VERSION ""

NS_ :

BS_:

BU_: Vector__XXX

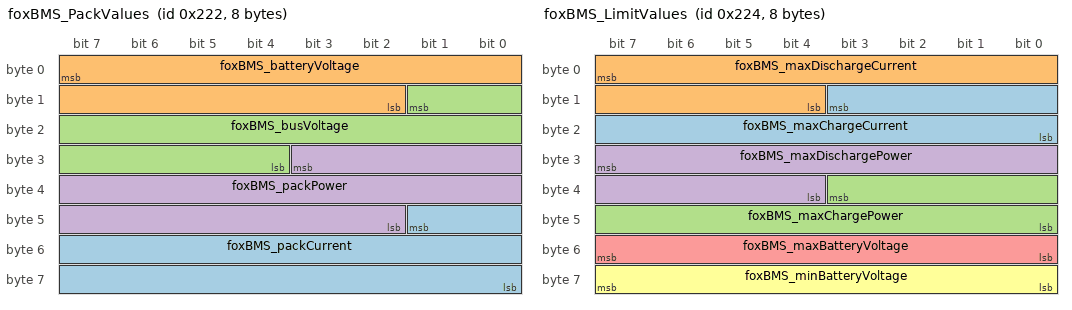
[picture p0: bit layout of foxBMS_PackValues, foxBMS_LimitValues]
BO_ 546 foxBMS_PackValues: 8 Vector__XXX
SG_ foxBMS_packCurrent : 41|18@0- (0.01,0) [-1310.72|1310.71] "A" Vector__XXX
SG_ foxBMS_batteryVoltage : 7|14@0+ (0.1,0) [0|1638.3] "V" Vector__XXX
SG_ foxBMS_busVoltage : 9|14@0+ (0.1,0) [0|1638.3] "V" Vector__XXX
SG_ foxBMS_packPower : 27|18@0- (0.01,0) [-1310.72|1310.71] "kW" Vector__XXX

BO_ 548 foxBMS_LimitValues: 8 Vector__XXX
SG_ foxBMS_maxChargeCurrent : 11|12@0+ (0.25,0) [0|1023.75] "A" Vector__XXX
SG_ foxBMS_maxDischargeCurrent : 7|12@0+ (0.25,0) [0|1023.75] "A" Vector__XXX
SG_ foxBMS_maxChargePower : 35|12@0+ (0.2,0) [0|819] "kW" Vector__XXX
SG_ foxBMS_maxDischargePower : 31|12@0+ (0.1,0) [0|409.5] "kW" Vector__XXX
SG_ foxBMS_maxBatteryVoltage : 55|8@0+ (4,0) [0|1020] "V" Vector__XXX
SG_ foxBMS_minBatteryVoltage : 63|8@0+ (4,0) [0|1020] "V" Vector__XXX

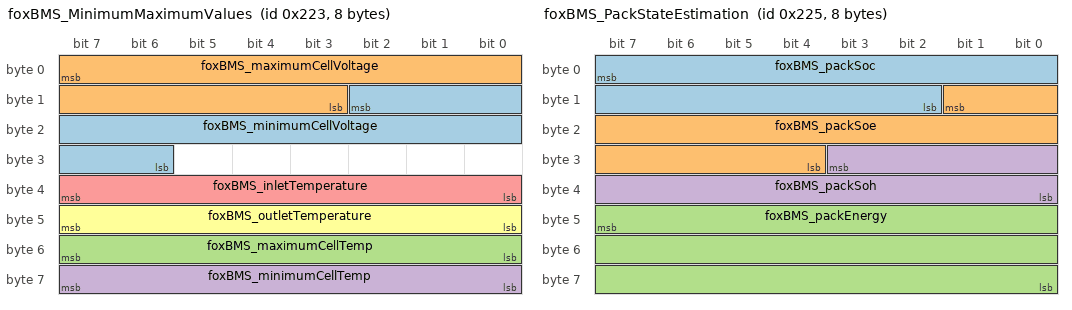
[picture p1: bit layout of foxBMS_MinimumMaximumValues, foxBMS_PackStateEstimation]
BO_ 547 foxBMS_MinimumMaximumValues: 8 Vector__XXX
SG_ foxBMS_minimumCellVoltage : 10|13@0+ (1,0) [0|8191] "mV" Vector__XXX
SG_ foxBMS_maximumCellVoltage : 7|13@0+ (1,0) [0|8191] "mV" Vector__XXX
SG_ foxBMS_maximumCellTemp : 55|8@0- (1,0) [-128|127] "degC" Vector__XXX
SG_ foxBMS_minimumCellTemp : 63|8@0- (1,0) [-128|127] "degC" Vector__XXX
SG_ foxBMS_inletTemperature : 39|8@0- (1,0) [-128|127] "degC" Vector__XXX
SG_ foxBMS_outletTemperature : 47|8@0- (1,0) [-128|127] "degC" Vector__XXX

BO_ 640 foxBMS_StringValues: 8 Vector__XXX
SG_ foxBMS_StringValues_Mux M : 7|3@0+ (1,0) [0|0] "" Vector__XXX
SG_ foxBMS_String0_current m0 : 19|18@0- (0.01,0) [-1310.72|1310.71] "A" Vector__XXX
SG_ foxBMS_String0_voltage m0 : 4|17@0+ (0.01,0) [0|1310.71] "V" Vector__XXX
SG_ foxBMS_String0_power m0 : 33|18@0- (0.01,0) [-1310.72|1310.71] "kW" Vector__XXX
SG_ foxBMS_String1_current m1 : 19|18@0- (0.01,0) [-1310.72|1310.71] "A" Vector__XXX
SG_ foxBMS_String1_voltage m1 : 4|17@0+ (0.01,0) [0|1310.71] "V" Vector__XXX
SG_ foxBMS_String1_power m1 : 33|18@0- (0.01,0) [-1310.72|1310.71] "kW" Vector__XXX
SG_ foxBMS_String2_current m2 : 19|18@0- (0.01,0) [-1310.72|1310.71] "A" Vector__XXX
SG_ foxBMS_String2_voltage m2 : 4|17@0+ (0.01,0) [0|1310.71] "V" Vector__XXX
SG_ foxBMS_String2_power m2 : 33|18@0- (0.01,0) [-1310.72|1310.71] "kW" Vector__XXX

BO_ 643 foxBMS_StringValues2: 8 Vector__XXX
SG_ foxBMS_StringValues2_Mux M : 7|4@0+ (1,0) [0|0] "" Vector__XXX
SG_ String0_energyCount m0 : 15|32@0- (1,0) [-2147483648|2147483647] "Wh" Vector__XXX
SG_ String1_energyCount1 m1 : 15|32@0- (1,0) [-2147483648|2147483647] "Wh" Vector__XXX
SG_ String1_energyCount2 m2 : 15|32@0- (1,0) [-2147483648|2147483647] "Wh" Vector__XXX

BO_ 549 foxBMS_PackStateEstimation: 8 Vector__XXX
SG_ foxBMS_packSoc : 7|14@0+ (0.01,0) [0|163.83] "%" Vector__XXX
SG_ foxBMS_packSoe : 9|14@0+ (0.01,0) [0|163.83] "%" Vector__XXX
SG_ foxBMS_packEnergy : 47|24@0+ (0.01,0) [0|167772.15] "kWh" Vector__XXX
SG_ foxBMS_packSoh : 27|12@0+ (0.025,0) [0|102.375] "%" Vector__XXX

BO_ 576 foxBMS_CellVoltage: 8 Vector__XXX
SG_ foxBMS_CellVoltage_Mux M : 7|8@0+ (1,0) [0|0] "" Vector__XXX
SG_ cellVoltage_0_invalidFlag m0 : 12|1@0+ (1,0) [0|1] "" Vector__XXX
SG_ cellVoltage_1_invalidFlag m0 : 13|1@0+ (1,0) [0|1] "" Vector__XXX
SG_ cellVoltage_2_invalidFlag m0 : 14|1@0+ (1,0) [0|1] "" Vector__XXX
SG_ cellVoltage_3_invalidFlag m0 : 15|1@0+ (1,0) [0|1] "" Vector__XXX
SG_ cellVoltage_0 m0 : 11|13@0+ (1,0) [0|8191] "mV" Vector__XXX
SG_ cell_voltage_1 m0 : 30|13@0+ (1,0) [0|8191] "mV" Vector__XXX
SG_ cell_voltage_2 m0 : 33|13@0+ (1,0) [0|8191] "mV" Vector__XXX
SG_ cell_voltage_3 m0 : 52|13@0+ (1,0) [0|8191] "mV" Vector__XXX
SG_ cellVoltage_4_invalidFlag m1 : 12|1@0+ (1,0) [0|1] "" Vector__XXX
SG_ cellVoltage_5_invalidFlag m1 : 13|1@0+ (1,0) [0|1] "" Vector__XXX
SG_ cellVoltage_6_invalidFlag m1 : 14|1@0+ (1,0) [0|1] "" Vector__XXX
SG_ cellVoltage_7_invalidFlag m1 : 15|1@0+ (1,0) [0|1] "" Vector__XXX
SG_ cellVoltage_4 m1 : 11|13@0+ (1,0) [0|8191] "mV" Vector__XXX
SG_ cell_voltage_5 m1 : 30|13@0+ (1,0) [0|8191] "mV" Vector__XXX
SG_ cell_voltage_6 m1 : 33|13@0+ (1,0) [0|8191] "mV" Vector__XXX
SG_ cell_voltage_7 m1 : 52|13@0+ (1,0) [0|8191] "mV" Vector__XXX
SG_ cellVoltage_8_invalidFlag m2 : 12|1@0+ (1,0) [0|1] "" Vector__XXX
SG_ cellVoltage_9_invalidFlag m2 : 13|1@0+ (1,0) [0|1] "" Vector__XXX
SG_ cellVoltage_10_invalidFlag m2 : 14|1@0+ (1,0) [0|1] "" Vector__XXX
SG_ cellVoltage_11_invalidFlag m2 : 15|1@0+ (1,0) [0|1] "" Vector__XXX
SG_ cellVoltage_8 m2 : 11|13@0+ (1,0) [0|8191] "mV" Vector__XXX
SG_ cell_voltage_9 m2 : 30|13@0+ (1,0) [0|8191] "mV" Vector__XXX
SG_ cell_voltage_10 m2 : 33|13@0+ (1,0) [0|8191] "mV" Vector__XXX
SG_ cell_voltage_11 m2 : 52|13@0+ (1,0) [0|8191] "mV" Vector__XXX
SG_ cellVoltage_12_invalidFlag m3 : 12|1@0+ (1,0) [0|1] "" Vector__XXX
SG_ cellVoltage_13_invalidFlag m3 : 13|1@0+ (1,0) [0|1] "" Vector__XXX
SG_ cellVoltage_14_invalidFlag m3 : 14|1@0+ (1,0) [0|1] "" Vector__XXX
SG_ cellVoltage_15_invalidFlag m3 : 15|1@0+ (1,0) [0|1] "" Vector__XXX
SG_ cellVoltage_12 m3 : 11|13@0+ (1,0) [0|8191] "mV" Vector__XXX
SG_ cell_voltage_13 m3 : 30|13@0+ (1,0) [0|8191] "mV" Vector__XXX
SG_ cell_voltage_14 m3 : 33|13@0+ (1,0) [0|8191] "mV" Vector__XXX
SG_ cell_voltage_15 m3 : 52|13@0+ (1,0) [0|8191] "mV" Vector__XXX
SG_ cellVoltage_16_invalidFlag m4 : 12|1@0+ (1,0) [0|1] "" Vector__XXX
SG_ cellVoltage_17_invalidFlag m4 : 13|1@0+ (1,0) [0|1] "" Vector__XXX
SG_ cellVoltage_18_invalidFlag m4 : 14|1@0+ (1,0) [0|1] "" Vector__XXX
SG_ cellVoltage_19_invalidFlag m4 : 15|1@0+ (1,0) [0|1] "" Vector__XXX
SG_ cellVoltage_16 m4 : 11|13@0+ (1,0) [0|8191] "mV" Vector__XXX
SG_ cell_voltage_17 m4 : 30|13@0+ (1,0) [0|8191] "mV" Vector__XXX
SG_ cell_voltage_18 m4 : 33|13@0+ (1,0) [0|8191] "mV" Vector__XXX
SG_ cell_voltage_19 m4 : 52|13@0+ (1,0) [0|8191] "mV" Vector__XXX
SG_ cellVoltage_20_invalidFlag m5 : 12|1@0+ (1,0) [0|1] "" Vector__XXX
SG_ cellVoltage_21_invalidFlag m5 : 13|1@0+ (1,0) [0|1] "" Vector__XXX
SG_ cellVoltage_22_invalidFlag m5 : 14|1@0+ (1,0) [0|1] "" Vector__XXX
SG_ cellVoltage_23_invalidFlag m5 : 15|1@0+ (1,0) [0|1] "" Vector__XXX
SG_ cellVoltage_20 m5 : 11|13@0+ (1,0) [0|8191] "mV" Vector__XXX
SG_ cell_voltage_21 m5 : 30|13@0+ (1,0) [0|8191] "mV" Vector__XXX
SG_ cell_voltage_22 m5 : 33|13@0+ (1,0) [0|8191] "mV" Vector__XXX
SG_ cell_voltage_23 m5 : 52|13@0+ (1,0) [0|8191] "mV" Vector__XXX
SG_ cellVoltage_24_invalidFlag m6 : 12|1@0+ (1,0) [0|1] "" Vector__XXX
SG_ cellVoltage_25_invalidFlag m6 : 13|1@0+ (1,0) [0|1] "" Vector__XXX
SG_ cellVoltage_26_invalidFlag m6 : 14|1@0+ (1,0) [0|1] "" Vector__XXX
SG_ cellVoltage_27_invalidFlag m6 : 15|1@0+ (1,0) [0|1] "" Vector__XXX
SG_ cellVoltage_24 m6 : 11|13@0+ (1,0) [0|8191] "mV" Vector__XXX
SG_ cell_voltage_25 m6 : 30|13@0+ (1,0) [0|8191] "mV" Vector__XXX
SG_ cell_voltage_26 m6 : 33|13@0+ (1,0) [0|8191] "mV" Vector__XXX
SG_ cell_voltage_27 m6 : 52|13@0+ (1,0) [0|8191] "mV" Vector__XXX
SG_ cellVoltage_28_invalidFlag m7 : 12|1@0+ (1,0) [0|1] "" Vector__XXX
SG_ cellVoltage_29_invalidFlag m7 : 13|1@0+ (1,0) [0|1] "" Vector__XXX
SG_ cellVoltage_30_invalidFlag m7 : 14|1@0+ (1,0) [0|1] "" Vector__XXX
SG_ cellVoltage_31_invalidFlag m7 : 15|1@0+ (1,0) [0|1] "" Vector__XXX
SG_ cellVoltage_28 m7 : 11|13@0+ (1,0) [0|8191] "mV" Vector__XXX
SG_ cell_voltage_29 m7 : 30|13@0+ (1,0) [0|8191] "mV" Vector__XXX
SG_ cell_voltage_30 m7 : 33|13@0+ (1,0) [0|8191] "mV" Vector__XXX
SG_ cell_voltage_31 m7 : 52|13@0+ (1,0) [0|8191] "mV" Vector__XXX
SG_ cellVoltage_32_invalidFlag m8 : 12|1@0+ (1,0) [0|1] "" Vector__XXX
SG_ cellVoltage_33_invalidFlag m8 : 13|1@0+ (1,0) [0|1] "" Vector__XXX
SG_ cellVoltage_34_invalidFlag m8 : 14|1@0+ (1,0) [0|1] "" Vector__XXX
SG_ cellVoltage_35_invalidFlag m8 : 15|1@0+ (1,0) [0|1] "" Vector__XXX
SG_ cellVoltage_32 m8 : 11|13@0+ (1,0) [0|8191] "mV" Vector__XXX
SG_ cell_voltage_33 m8 : 30|13@0+ (1,0) [0|8191] "mV" Vector__XXX
SG_ cell_voltage_34 m8 : 33|13@0+ (1,0) [0|8191] "mV" Vector__XXX
SG_ cell_voltage_35 m8 : 52|13@0+ (1,0) [0|8191] "mV" Vector__XXX
SG_ cellVoltage_36_invalidFlag m9 : 12|1@0+ (1,0) [0|1] "" Vector__XXX
SG_ cellVoltage_37_invalidFlag m9 : 13|1@0+ (1,0) [0|1] "" Vector__XXX
SG_ cellVoltage_38_invalidFlag m9 : 14|1@0+ (1,0) [0|1] "" Vector__XXX
SG_ cellVoltage_39_invalidFlag m9 : 15|1@0+ (1,0) [0|1] "" Vector__XXX
SG_ cellVoltage_36 m9 : 11|13@0+ (1,0) [0|8191] "mV" Vector__XXX
SG_ cell_voltage_37 m9 : 30|13@0+ (1,0) [0|8191] "mV" Vector__XXX
SG_ cell_voltage_38 m9 : 33|13@0+ (1,0) [0|8191] "mV" Vector__XXX
SG_ cell_voltage_39 m9 : 52|13@0+ (1,0) [0|8191] "mV" Vector__XXX
SG_ cellVoltage_40_invalidFlag m10 : 12|1@0+ (1,0) [0|1] "" Vector__XXX
SG_ cellVoltage_41_invalidFlag m10 : 13|1@0+ (1,0) [0|1] "" Vector__XXX
SG_ cellVoltage_42_invalidFlag m10 : 14|1@0+ (1,0) [0|1] "" Vector__XXX
SG_ cellVoltage_43_invalidFlag m10 : 15|1@0+ (1,0) [0|1] "" Vector__XXX
SG_ cellVoltage_40 m10 : 11|13@0+ (1,0) [0|8191] "mV" Vector__XXX
SG_ cell_voltage_41 m10 : 30|13@0+ (1,0) [0|8191] "mV" Vector__XXX
SG_ cell_voltage_42 m10 : 33|13@0+ (1,0) [0|8191] "mV" Vector__XXX
SG_ cell_voltage_43 m10 : 52|13@0+ (1,0) [0|8191] "mV" Vector__XXX
SG_ cellVoltage_44_invalidFlag m11 : 12|1@0+ (1,0) [0|1] "" Vector__XXX
SG_ cellVoltage_45_invalidFlag m11 : 13|1@0+ (1,0) [0|1] "" Vector__XXX
SG_ cellVoltage_46_invalidFlag m11 : 14|1@0+ (1,0) [0|1] "" Vector__XXX
SG_ cellVoltage_47_invalidFlag m11 : 15|1@0+ (1,0) [0|1] "" Vector__XXX
SG_ cellVoltage_44 m11 : 11|13@0+ (1,0) [0|8191] "mV" Vector__XXX
SG_ cell_voltage_45 m11 : 30|13@0+ (1,0) [0|8191] "mV" Vector__XXX
SG_ cell_voltage_46 m11 : 33|13@0+ (1,0) [0|8191] "mV" Vector__XXX
SG_ cell_voltage_47 m11 : 52|13@0+ (1,0) [0|8191] "mV" Vector__XXX
SG_ cellVoltage_48_invalidFlag m12 : 12|1@0+ (1,0) [0|1] "" Vector__XXX
SG_ cellVoltage_49_invalidFlag m12 : 13|1@0+ (1,0) [0|1] "" Vector__XXX
SG_ cellVoltage_50_invalidFlag m12 : 14|1@0+ (1,0) [0|1] "" Vector__XXX
SG_ cellVoltage_51_invalidFlag m12 : 15|1@0+ (1,0) [0|1] "" Vector__XXX
SG_ cellVoltage_48 m12 : 11|13@0+ (1,0) [0|8191] "mV" Vector__XXX
SG_ cell_voltage_49 m12 : 30|13@0+ (1,0) [0|8191] "mV" Vector__XXX
SG_ cell_voltage_50 m12 : 33|13@0+ (1,0) [0|8191] "mV" Vector__XXX
SG_ cell_voltage_51 m12 : 52|13@0+ (1,0) [0|8191] "mV" Vector__XXX
SG_ cellVoltage_52_invalidFlag m13 : 12|1@0+ (1,0) [0|1] "" Vector__XXX
SG_ cellVoltage_53_invalidFlag m13 : 13|1@0+ (1,0) [0|1] "" Vector__XXX
SG_ cellVoltage_54_invalidFlag m13 : 14|1@0+ (1,0) [0|1] "" Vector__XXX
SG_ cellVoltage_55_invalidFlag m13 : 15|1@0+ (1,0) [0|1] "" Vector__XXX
SG_ cellVoltage_52 m13 : 11|13@0+ (1,0) [0|8191] "mV" Vector__XXX
SG_ cell_voltage_53 m13 : 30|13@0+ (1,0) [0|8191] "mV" Vector__XXX
SG_ cell_voltage_54 m13 : 33|13@0+ (1,0) [0|8191] "mV" Vector__XXX
SG_ cell_voltage_55 m13 : 52|13@0+ (1,0) [0|8191] "mV" Vector__XXX
SG_ cellVoltage_56_invalidFlag m14 : 12|1@0+ (1,0) [0|1] "" Vector__XXX
SG_ cellVoltage_57_invalidFlag m14 : 13|1@0+ (1,0) [0|1] "" Vector__XXX
SG_ cellVoltage_58_invalidFlag m14 : 14|1@0+ (1,0) [0|1] "" Vector__XXX
SG_ cellVoltage_59_invalidFlag m14 : 15|1@0+ (1,0) [0|1] "" Vector__XXX
SG_ cellVoltage_56 m14 : 11|13@0+ (1,0) [0|8191] "mV" Vector__XXX
SG_ cell_voltage_57 m14 : 30|13@0+ (1,0) [0|8191] "mV" Vector__XXX
SG_ cell_voltage_58 m14 : 33|13@0+ (1,0) [0|8191] "mV" Vector__XXX
SG_ cell_voltage_59 m14 : 52|13@0+ (1,0) [0|8191] "mV" Vector__XXX
SG_ cellVoltage_60_invalidFlag m15 : 12|1@0+ (1,0) [0|1] "" Vector__XXX
SG_ cellVoltage_61_invalidFlag m15 : 13|1@0+ (1,0) [0|1] "" Vector__XXX
SG_ cellVoltage_62_invalidFlag m15 : 14|1@0+ (1,0) [0|1] "" Vector__XXX
SG_ cellVoltage_63_invalidFlag m15 : 15|1@0+ (1,0) [0|1] "" Vector__XXX
SG_ cellVoltage_60 m15 : 11|13@0+ (1,0) [0|8191] "mV" Vector__XXX
SG_ cell_voltage_61 m15 : 30|13@0+ (1,0) [0|8191] "mV" Vector__XXX
SG_ cell_voltage_62 m15 : 33|13@0+ (1,0) [0|8191] "mV" Vector__XXX
SG_ cell_voltage_63 m15 : 52|13@0+ (1,0) [0|8191] "mV" Vector__XXX
SG_ cellVoltage_64_invalidFlag m16 : 12|1@0+ (1,0) [0|1] "" Vector__XXX
SG_ cellVoltage_65_invalidFlag m16 : 13|1@0+ (1,0) [0|1] "" Vector__XXX
SG_ cellVoltage_66_invalidFlag m16 : 14|1@0+ (1,0) [0|1] "" Vector__XXX
SG_ cellVoltage_67_invalidFlag m16 : 15|1@0+ (1,0) [0|1] "" Vector__XXX
SG_ cellVoltage_64 m16 : 11|13@0+ (1,0) [0|8191] "mV" Vector__XXX
SG_ cell_voltage_65 m16 : 30|13@0+ (1,0) [0|8191] "mV" Vector__XXX
SG_ cell_voltage_66 m16 : 33|13@0+ (1,0) [0|8191] "mV" Vector__XXX
SG_ cell_voltage_67 m16 : 52|13@0+ (1,0) [0|8191] "mV" Vector__XXX
SG_ cellVoltage_68_invalidFlag m17 : 12|1@0+ (1,0) [0|1] "" Vector__XXX
SG_ cellVoltage_69_invalidFlag m17 : 13|1@0+ (1,0) [0|1] "" Vector__XXX
SG_ cellVoltage_70_invalidFlag m17 : 14|1@0+ (1,0) [0|1] "" Vector__XXX
SG_ cellVoltage_71_invalidFlag m17 : 15|1@0+ (1,0) [0|1] "" Vector__XXX
SG_ cellVoltage_68 m17 : 11|13@0+ (1,0) [0|8191] "mV" Vector__XXX
SG_ cell_voltage_69 m17 : 30|13@0+ (1,0) [0|8191] "mV" Vector__XXX
SG_ cell_voltage_70 m17 : 33|13@0+ (1,0) [0|8191] "mV" Vector__XXX
SG_ cell_voltage_71 m17 : 52|13@0+ (1,0) [0|8191] "mV" Vector__XXX
SG_ cellVoltage_72_invalidFlag m18 : 12|1@0+ (1,0) [0|1] "" Vector__XXX
SG_ cellVoltage_73_invalidFlag m18 : 13|1@0+ (1,0) [0|1] "" Vector__XXX
SG_ cellVoltage_74_invalidFlag m18 : 14|1@0+ (1,0) [0|1] "" Vector__XXX
SG_ cellVoltage_75_invalidFlag m18 : 15|1@0+ (1,0) [0|1] "" Vector__XXX
SG_ cellVoltage_72 m18 : 11|13@0+ (1,0) [0|8191] "mV" Vector__XXX
SG_ cell_voltage_73 m18 : 30|13@0+ (1,0) [0|8191] "mV" Vector__XXX
SG_ cell_voltage_74 m18 : 33|13@0+ (1,0) [0|8191] "mV" Vector__XXX
SG_ cell_voltage_75 m18 : 52|13@0+ (1,0) [0|8191] "mV" Vector__XXX
SG_ cellVoltage_76_invalidFlag m19 : 12|1@0+ (1,0) [0|1] "" Vector__XXX
SG_ cellVoltage_77_invalidFlag m19 : 13|1@0+ (1,0) [0|1] "" Vector__XXX
SG_ cellVoltage_78_invalidFlag m19 : 14|1@0+ (1,0) [0|1] "" Vector__XXX
SG_ cellVoltage_79_invalidFlag m19 : 15|1@0+ (1,0) [0|1] "" Vector__XXX
SG_ cellVoltage_76 m19 : 11|13@0+ (1,0) [0|8191] "mV" Vector__XXX
SG_ cell_voltage_77 m19 : 30|13@0+ (1,0) [0|8191] "mV" Vector__XXX
SG_ cell_voltage_78 m19 : 33|13@0+ (1,0) [0|8191] "mV" Vector__XXX
SG_ cell_voltage_79 m19 : 52|13@0+ (1,0) [0|8191] "mV" Vector__XXX
SG_ cellVoltage_80_invalidFlag m20 : 12|1@0+ (1,0) [0|1] "" Vector__XXX
SG_ cellVoltage_81_invalidFlag m20 : 13|1@0+ (1,0) [0|1] "" Vector__XXX
SG_ cellVoltage_82_invalidFlag m20 : 14|1@0+ (1,0) [0|1] "" Vector__XXX
SG_ cellVoltage_83_invalidFlag m20 : 15|1@0+ (1,0) [0|1] "" Vector__XXX
SG_ cellVoltage_80 m20 : 11|13@0+ (1,0) [0|8191] "mV" Vector__XXX
SG_ cell_voltage_81 m20 : 30|13@0+ (1,0) [0|8191] "mV" Vector__XXX
SG_ cell_voltage_82 m20 : 33|13@0+ (1,0) [0|8191] "mV" Vector__XXX
SG_ cell_voltage_83 m20 : 52|13@0+ (1,0) [0|8191] "mV" Vector__XXX
SG_ cellVoltage_84_invalidFlag m21 : 12|1@0+ (1,0) [0|1] "" Vector__XXX
SG_ cellVoltage_85_invalidFlag m21 : 13|1@0+ (1,0) [0|1] "" Vector__XXX
SG_ cellVoltage_86_invalidFlag m21 : 14|1@0+ (1,0) [0|1] "" Vector__XXX
SG_ cellVoltage_87_invalidFlag m21 : 15|1@0+ (1,0) [0|1] "" Vector__XXX
SG_ cellVoltage_84 m21 : 11|13@0+ (1,0) [0|8191] "mV" Vector__XXX
SG_ cell_voltage_85 m21 : 30|13@0+ (1,0) [0|8191] "mV" Vector__XXX
SG_ cell_voltage_86 m21 : 33|13@0+ (1,0) [0|8191] "mV" Vector__XXX
SG_ cell_voltage_87 m21 : 52|13@0+ (1,0) [0|8191] "mV" Vector__XXX
SG_ cellVoltage_88_invalidFlag m22 : 12|1@0+ (1,0) [0|1] "" Vector__XXX
SG_ cellVoltage_89_invalidFlag m22 : 13|1@0+ (1,0) [0|1] "" Vector__XXX
SG_ cellVoltage_90_invalidFlag m22 : 14|1@0+ (1,0) [0|1] "" Vector__XXX
SG_ cellVoltage_91_invalidFlag m22 : 15|1@0+ (1,0) [0|1] "" Vector__XXX
SG_ cellVoltage_88 m22 : 11|13@0+ (1,0) [0|8191] "mV" Vector__XXX
SG_ cell_voltage_89 m22 : 30|13@0+ (1,0) [0|8191] "mV" Vector__XXX
SG_ cell_voltage_90 m22 : 33|13@0+ (1,0) [0|8191] "mV" Vector__XXX
SG_ cell_voltage_91 m22 : 52|13@0+ (1,0) [0|8191] "mV" Vector__XXX
SG_ cellVoltage_92_invalidFlag m23 : 12|1@0+ (1,0) [0|1] "" Vector__XXX
SG_ cellVoltage_93_invalidFlag m23 : 13|1@0+ (1,0) [0|1] "" Vector__XXX
SG_ cellVoltage_94_invalidFlag m23 : 14|1@0+ (1,0) [0|1] "" Vector__XXX
SG_ cellVoltage_95_invalidFlag m23 : 15|1@0+ (1,0) [0|1] "" Vector__XXX
SG_ cellVoltage_92 m23 : 11|13@0+ (1,0) [0|8191] "mV" Vector__XXX
SG_ cell_voltage_93 m23 : 30|13@0+ (1,0) [0|8191] "mV" Vector__XXX
SG_ cell_voltage_94 m23 : 33|13@0+ (1,0) [0|8191] "mV" Vector__XXX
SG_ cell_voltage_95 m23 : 52|13@0+ (1,0) [0|8191] "mV" Vector__XXX
SG_ cellVoltage_96_invalidFlag m24 : 12|1@0+ (1,0) [0|1] "" Vector__XXX
SG_ cellVoltage_97_invalidFlag m24 : 13|1@0+ (1,0) [0|1] "" Vector__XXX
SG_ cellVoltage_98_invalidFlag m24 : 14|1@0+ (1,0) [0|1] "" Vector__XXX
SG_ cellVoltage_99_invalidFlag m24 : 15|1@0+ (1,0) [0|1] "" Vector__XXX
SG_ cellVoltage_96 m24 : 11|13@0+ (1,0) [0|8191] "mV" Vector__XXX
SG_ cell_voltage_97 m24 : 30|13@0+ (1,0) [0|8191] "mV" Vector__XXX
SG_ cell_voltage_98 m24 : 33|13@0+ (1,0) [0|8191] "mV" Vector__XXX
SG_ cell_voltage_99 m24 : 52|13@0+ (1,0) [0|8191] "mV" Vector__XXX
SG_ cellVoltage_100_invalidFlag m25 : 12|1@0+ (1,0) [0|1] "" Vector__XXX
SG_ cellVoltage_101_invalidFlag m25 : 13|1@0+ (1,0) [0|1] "" Vector__XXX
SG_ cellVoltage_102_invalidFlag m25 : 14|1@0+ (1,0) [0|1] "" Vector__XXX
SG_ cellVoltage_103_invalidFlag m25 : 15|1@0+ (1,0) [0|1] "" Vector__XXX
SG_ cellVoltage_100 m25 : 11|13@0+ (1,0) [0|8191] "mV" Vector__XXX
SG_ cell_voltage_101 m25 : 30|13@0+ (1,0) [0|8191] "mV" Vector__XXX
SG_ cell_voltage_102 m25 : 33|13@0+ (1,0) [0|8191] "mV" Vector__XXX
SG_ cell_voltage_103 m25 : 52|13@0+ (1,0) [0|8191] "mV" Vector__XXX
SG_ cellVoltage_104_invalidFlag m26 : 12|1@0+ (1,0) [0|1] "" Vector__XXX
SG_ cellVoltage_105_invalidFlag m26 : 13|1@0+ (1,0) [0|1] "" Vector__XXX
SG_ cellVoltage_106_invalidFlag m26 : 14|1@0+ (1,0) [0|1] "" Vector__XXX
SG_ cellVoltage_107_invalidFlag m26 : 15|1@0+ (1,0) [0|1] "" Vector__XXX
SG_ cellVoltage_104 m26 : 11|13@0+ (1,0) [0|8191] "mV" Vector__XXX
SG_ cell_voltage_105 m26 : 30|13@0+ (1,0) [0|8191] "mV" Vector__XXX
SG_ cell_voltage_106 m26 : 33|13@0+ (1,0) [0|8191] "mV" Vector__XXX
SG_ cell_voltage_107 m26 : 52|13@0+ (1,0) [0|8191] "mV" Vector__XXX
SG_ cellVoltage_108_invalidFlag m27 : 12|1@0+ (1,0) [0|1] "" Vector__XXX
SG_ cellVoltage_109_invalidFlag m27 : 13|1@0+ (1,0) [0|1] "" Vector__XXX
SG_ cellVoltage_110_invalidFlag m27 : 14|1@0+ (1,0) [0|1] "" Vector__XXX
SG_ cellVoltage_111_invalidFlag m27 : 15|1@0+ (1,0) [0|1] "" Vector__XXX
SG_ cellVoltage_108 m27 : 11|13@0+ (1,0) [0|8191] "mV" Vector__XXX
SG_ cell_voltage_109 m27 : 30|13@0+ (1,0) [0|8191] "mV" Vector__XXX
SG_ cell_voltage_110 m27 : 33|13@0+ (1,0) [0|8191] "mV" Vector__XXX
SG_ cell_voltage_111 m27 : 52|13@0+ (1,0) [0|8191] "mV" Vector__XXX
SG_ cellVoltage_112_invalidFlag m28 : 12|1@0+ (1,0) [0|1] "" Vector__XXX
SG_ cellVoltage_113_invalidFlag m28 : 13|1@0+ (1,0) [0|1] "" Vector__XXX
SG_ cellVoltage_114_invalidFlag m28 : 14|1@0+ (1,0) [0|1] "" Vector__XXX
SG_ cellVoltage_115_invalidFlag m28 : 15|1@0+ (1,0) [0|1] "" Vector__XXX
SG_ cellVoltage_112 m28 : 11|13@0+ (1,0) [0|8191] "mV" Vector__XXX
SG_ cell_voltage_113 m28 : 30|13@0+ (1,0) [0|8191] "mV" Vector__XXX
SG_ cell_voltage_114 m28 : 33|13@0+ (1,0) [0|8191] "mV" Vector__XXX
SG_ cell_voltage_115 m28 : 52|13@0+ (1,0) [0|8191] "mV" Vector__XXX
SG_ cellVoltage_116_invalidFlag m29 : 12|1@0+ (1,0) [0|1] "" Vector__XXX
SG_ cellVoltage_117_invalidFlag m29 : 13|1@0+ (1,0) [0|1] "" Vector__XXX
SG_ cellVoltage_118_invalidFlag m29 : 14|1@0+ (1,0) [0|1] "" Vector__XXX
SG_ cellVoltage_119_invalidFlag m29 : 15|1@0+ (1,0) [0|1] "" Vector__XXX
SG_ cellVoltage_116 m29 : 11|13@0+ (1,0) [0|8191] "mV" Vector__XXX
SG_ cell_voltage_117 m29 : 30|13@0+ (1,0) [0|8191] "mV" Vector__XXX
SG_ cell_voltage_118 m29 : 33|13@0+ (1,0) [0|8191] "mV" Vector__XXX
SG_ cell_voltage_119 m29 : 52|13@0+ (1,0) [0|8191] "mV" Vector__XXX
SG_ cellVoltage_120_invalidFlag m30 : 12|1@0+ (1,0) [0|1] "" Vector__XXX
SG_ cellVoltage_121_invalidFlag m30 : 13|1@0+ (1,0) [0|1] "" Vector__XXX
SG_ cellVoltage_122_invalidFlag m30 : 14|1@0+ (1,0) [0|1] "" Vector__XXX
SG_ cellVoltage_123_invalidFlag m30 : 15|1@0+ (1,0) [0|1] "" Vector__XXX
SG_ cellVoltage_120 m30 : 11|13@0+ (1,0) [0|8191] "mV" Vector__XXX
SG_ cell_voltage_121 m30 : 30|13@0+ (1,0) [0|8191] "mV" Vector__XXX
SG_ cell_voltage_122 m30 : 33|13@0+ (1,0) [0|8191] "mV" Vector__XXX
SG_ cell_voltage_123 m30 : 52|13@0+ (1,0) [0|8191] "mV" Vector__XXX
SG_ cellVoltage_124_invalidFlag m31 : 12|1@0+ (1,0) [0|1] "" Vector__XXX
SG_ cellVoltage_125_invalidFlag m31 : 13|1@0+ (1,0) [0|1] "" Vector__XXX
SG_ cellVoltage_126_invalidFlag m31 : 14|1@0+ (1,0) [0|1] "" Vector__XXX
SG_ cellVoltage_127_invalidFlag m31 : 15|1@0+ (1,0) [0|1] "" Vector__XXX
SG_ cellVoltage_124 m31 : 11|13@0+ (1,0) [0|8191] "mV" Vector__XXX
SG_ cell_voltage_125 m31 : 30|13@0+ (1,0) [0|8191] "mV" Vector__XXX
SG_ cell_voltage_126 m31 : 33|13@0+ (1,0) [0|8191] "mV" Vector__XXX
SG_ cell_voltage_127 m31 : 52|13@0+ (1,0) [0|8191] "mV" Vector__XXX
SG_ cellVoltage_128_invalidFlag m32 : 12|1@0+ (1,0) [0|1] "" Vector__XXX
SG_ cellVoltage_129_invalidFlag m32 : 13|1@0+ (1,0) [0|1] "" Vector__XXX
SG_ cellVoltage_130_invalidFlag m32 : 14|1@0+ (1,0) [0|1] "" Vector__XXX
SG_ cellVoltage_131_invalidFlag m32 : 15|1@0+ (1,0) [0|1] "" Vector__XXX
SG_ cellVoltage_128 m32 : 11|13@0+ (1,0) [0|8191] "mV" Vector__XXX
SG_ cell_voltage_129 m32 : 30|13@0+ (1,0) [0|8191] "mV" Vector__XXX
SG_ cell_voltage_130 m32 : 33|13@0+ (1,0) [0|8191] "mV" Vector__XXX
SG_ cell_voltage_131 m32 : 52|13@0+ (1,0) [0|8191] "mV" Vector__XXX
SG_ cellVoltage_132_invalidFlag m33 : 12|1@0+ (1,0) [0|1] "" Vector__XXX
SG_ cellVoltage_133_invalidFlag m33 : 13|1@0+ (1,0) [0|1] "" Vector__XXX
SG_ cellVoltage_134_invalidFlag m33 : 14|1@0+ (1,0) [0|1] "" Vector__XXX
SG_ cellVoltage_135_invalidFlag m33 : 15|1@0+ (1,0) [0|1] "" Vector__XXX
SG_ cellVoltage_132 m33 : 11|13@0+ (1,0) [0|8191] "mV" Vector__XXX
SG_ cell_voltage_133 m33 : 30|13@0+ (1,0) [0|8191] "mV" Vector__XXX
SG_ cell_voltage_134 m33 : 33|13@0+ (1,0) [0|8191] "mV" Vector__XXX
SG_ cell_voltage_135 m33 : 52|13@0+ (1,0) [0|8191] "mV" Vector__XXX
SG_ cellVoltage_136_invalidFlag m34 : 12|1@0+ (1,0) [0|1] "" Vector__XXX
SG_ cellVoltage_137_invalidFlag m34 : 13|1@0+ (1,0) [0|1] "" Vector__XXX
SG_ cellVoltage_138_invalidFlag m34 : 14|1@0+ (1,0) [0|1] "" Vector__XXX
SG_ cellVoltage_139_invalidFlag m34 : 15|1@0+ (1,0) [0|1] "" Vector__XXX
SG_ cellVoltage_136 m34 : 11|13@0+ (1,0) [0|8191] "mV" Vector__XXX
SG_ cell_voltage_137 m34 : 30|13@0+ (1,0) [0|8191] "mV" Vector__XXX
SG_ cell_voltage_138 m34 : 33|13@0+ (1,0) [0|8191] "mV" Vector__XXX
SG_ cell_voltage_139 m34 : 52|13@0+ (1,0) [0|8191] "mV" Vector__XXX
SG_ cellVoltage_140_invalidFlag m35 : 12|1@0+ (1,0) [0|1] "" Vector__XXX
SG_ cellVoltage_141_invalidFlag m35 : 13|1@0+ (1,0) [0|1] "" Vector__XXX
SG_ cellVoltage_142_invalidFlag m35 : 14|1@0+ (1,0) [0|1] "" Vector__XXX
SG_ cellVoltage_143_invalidFlag m35 : 15|1@0+ (1,0) [0|1] "" Vector__XXX
SG_ cellVoltage_140 m35 : 11|13@0+ (1,0) [0|8191] "mV" Vector__XXX
SG_ cell_voltage_141 m35 : 30|13@0+ (1,0) [0|8191] "mV" Vector__XXX
SG_ cell_voltage_142 m35 : 33|13@0+ (1,0) [0|8191] "mV" Vector__XXX
SG_ cell_voltage_143 m35 : 52|13@0+ (1,0) [0|8191] "mV" Vector__XXX
SG_ cellVoltage_144_invalidFlag m36 : 12|1@0+ (1,0) [0|1] "" Vector__XXX
SG_ cellVoltage_145_invalidFlag m36 : 13|1@0+ (1,0) [0|1] "" Vector__XXX
SG_ cellVoltage_146_invalidFlag m36 : 14|1@0+ (1,0) [0|1] "" Vector__XXX
SG_ cellVoltage_147_invalidFlag m36 : 15|1@0+ (1,0) [0|1] "" Vector__XXX
SG_ cellVoltage_144 m36 : 11|13@0+ (1,0) [0|8191] "mV" Vector__XXX
SG_ cell_voltage_145 m36 : 30|13@0+ (1,0) [0|8191] "mV" Vector__XXX
SG_ cell_voltage_146 m36 : 33|13@0+ (1,0) [0|8191] "mV" Vector__XXX
SG_ cell_voltage_147 m36 : 52|13@0+ (1,0) [0|8191] "mV" Vector__XXX
SG_ cellVoltage_148_invalidFlag m37 : 12|1@0+ (1,0) [0|1] "" Vector__XXX
SG_ cellVoltage_149_invalidFlag m37 : 13|1@0+ (1,0) [0|1] "" Vector__XXX
SG_ cellVoltage_150_invalidFlag m37 : 14|1@0+ (1,0) [0|1] "" Vector__XXX
SG_ cellVoltage_151_invalidFlag m37 : 15|1@0+ (1,0) [0|1] "" Vector__XXX
SG_ cellVoltage_148 m37 : 11|13@0+ (1,0) [0|8191] "mV" Vector__XXX
SG_ cell_voltage_149 m37 : 30|13@0+ (1,0) [0|8191] "mV" Vector__XXX
SG_ cell_voltage_150 m37 : 33|13@0+ (1,0) [0|8191] "mV" Vector__XXX
SG_ cell_voltage_151 m37 : 52|13@0+ (1,0) [0|8191] "mV" Vector__XXX
SG_ cellVoltage_152_invalidFlag m38 : 12|1@0+ (1,0) [0|1] "" Vector__XXX
SG_ cellVoltage_153_invalidFlag m38 : 13|1@0+ (1,0) [0|1] "" Vector__XXX
SG_ cellVoltage_154_invalidFlag m38 : 14|1@0+ (1,0) [0|1] "" Vector__XXX
SG_ cellVoltage_155_invalidFlag m38 : 15|1@0+ (1,0) [0|1] "" Vector__XXX
SG_ cellVoltage_152 m38 : 11|13@0+ (1,0) [0|8191] "mV" Vector__XXX
SG_ cell_voltage_153 m38 : 30|13@0+ (1,0) [0|8191] "mV" Vector__XXX
SG_ cell_voltage_154 m38 : 33|13@0+ (1,0) [0|8191] "mV" Vector__XXX
SG_ cell_voltage_155 m38 : 52|13@0+ (1,0) [0|8191] "mV" Vector__XXX
SG_ cellVoltage_156_invalidFlag m39 : 12|1@0+ (1,0) [0|1] "" Vector__XXX
SG_ cellVoltage_157_invalidFlag m39 : 13|1@0+ (1,0) [0|1] "" Vector__XXX
SG_ cellVoltage_158_invalidFlag m39 : 14|1@0+ (1,0) [0|1] "" Vector__XXX
SG_ cellVoltage_159_invalidFlag m39 : 15|1@0+ (1,0) [0|1] "" Vector__XXX
SG_ cellVoltage_156 m39 : 11|13@0+ (1,0) [0|8191] "mV" Vector__XXX
SG_ cell_voltage_157 m39 : 30|13@0+ (1,0) [0|8191] "mV" Vector__XXX
SG_ cell_voltage_158 m39 : 33|13@0+ (1,0) [0|8191] "mV" Vector__XXX
SG_ cell_voltage_159 m39 : 52|13@0+ (1,0) [0|8191] "mV" Vector__XXX
SG_ cellVoltage_160_invalidFlag m40 : 12|1@0+ (1,0) [0|1] "" Vector__XXX
SG_ cellVoltage_161_invalidFlag m40 : 13|1@0+ (1,0) [0|1] "" Vector__XXX
SG_ cellVoltage_162_invalidFlag m40 : 14|1@0+ (1,0) [0|1] "" Vector__XXX
SG_ cellVoltage_163_invalidFlag m40 : 15|1@0+ (1,0) [0|1] "" Vector__XXX
SG_ cellVoltage_160 m40 : 11|13@0+ (1,0) [0|8191] "mV" Vector__XXX
SG_ cell_voltage_161 m40 : 30|13@0+ (1,0) [0|8191] "mV" Vector__XXX
SG_ cell_voltage_162 m40 : 33|13@0+ (1,0) [0|8191] "mV" Vector__XXX
SG_ cell_voltage_163 m40 : 52|13@0+ (1,0) [0|8191] "mV" Vector__XXX
SG_ cellVoltage_164_invalidFlag m41 : 12|1@0+ (1,0) [0|1] "" Vector__XXX
SG_ cellVoltage_165_invalidFlag m41 : 13|1@0+ (1,0) [0|1] "" Vector__XXX
SG_ cellVoltage_166_invalidFlag m41 : 14|1@0+ (1,0) [0|1] "" Vector__XXX
SG_ cellVoltage_167_invalidFlag m41 : 15|1@0+ (1,0) [0|1] "" Vector__XXX
SG_ cellVoltage_164 m41 : 11|13@0+ (1,0) [0|8191] "mV" Vector__XXX
SG_ cell_voltage_165 m41 : 30|13@0+ (1,0) [0|8191] "mV" Vector__XXX
SG_ cell_voltage_166 m41 : 33|13@0+ (1,0) [0|8191] "mV" Vector__XXX
SG_ cell_voltage_167 m41 : 52|13@0+ (1,0) [0|8191] "mV" Vector__XXX
SG_ cellVoltage_168_invalidFlag m42 : 12|1@0+ (1,0) [0|1] "" Vector__XXX
SG_ cellVoltage_169_invalidFlag m42 : 13|1@0+ (1,0) [0|1] "" Vector__XXX
SG_ cellVoltage_170_invalidFlag m42 : 14|1@0+ (1,0) [0|1] "" Vector__XXX
SG_ cellVoltage_171_invalidFlag m42 : 15|1@0+ (1,0) [0|1] "" Vector__XXX
SG_ cellVoltage_168 m42 : 11|13@0+ (1,0) [0|8191] "mV" Vector__XXX
SG_ cell_voltage_169 m42 : 30|13@0+ (1,0) [0|8191] "mV" Vector__XXX
SG_ cell_voltage_170 m42 : 33|13@0+ (1,0) [0|8191] "mV" Vector__XXX
SG_ cell_voltage_171 m42 : 52|13@0+ (1,0) [0|8191] "mV" Vector__XXX
SG_ cellVoltage_172_invalidFlag m43 : 12|1@0+ (1,0) [0|1] "" Vector__XXX
SG_ cellVoltage_173_invalidFlag m43 : 13|1@0+ (1,0) [0|1] "" Vector__XXX
SG_ cellVoltage_174_invalidFlag m43 : 14|1@0+ (1,0) [0|1] "" Vector__XXX
SG_ cellVoltage_175_invalidFlag m43 : 15|1@0+ (1,0) [0|1] "" Vector__XXX
SG_ cellVoltage_172 m43 : 11|13@0+ (1,0) [0|8191] "mV" Vector__XXX
SG_ cell_voltage_173 m43 : 30|13@0+ (1,0) [0|8191] "mV" Vector__XXX
SG_ cell_voltage_174 m43 : 33|13@0+ (1,0) [0|8191] "mV" Vector__XXX
SG_ cell_voltage_175 m43 : 52|13@0+ (1,0) [0|8191] "mV" Vector__XXX
SG_ cellVoltage_176_invalidFlag m44 : 12|1@0+ (1,0) [0|1] "" Vector__XXX
SG_ cellVoltage_177_invalidFlag m44 : 13|1@0+ (1,0) [0|1] "" Vector__XXX
SG_ cellVoltage_178_invalidFlag m44 : 14|1@0+ (1,0) [0|1] "" Vector__XXX
SG_ cellVoltage_179_invalidFlag m44 : 15|1@0+ (1,0) [0|1] "" Vector__XXX
SG_ cellVoltage_176 m44 : 11|13@0+ (1,0) [0|8191] "mV" Vector__XXX
SG_ cell_voltage_177 m44 : 30|13@0+ (1,0) [0|8191] "mV" Vector__XXX
SG_ cell_voltage_178 m44 : 33|13@0+ (1,0) [0|8191] "mV" Vector__XXX
SG_ cell_voltage_179 m44 : 52|13@0+ (1,0) [0|8191] "mV" Vector__XXX
SG_ cellVoltage_180_invalidFlag m45 : 12|1@0+ (1,0) [0|1] "" Vector__XXX
SG_ cellVoltage_181_invalidFlag m45 : 13|1@0+ (1,0) [0|1] "" Vector__XXX
SG_ cellVoltage_182_invalidFlag m45 : 14|1@0+ (1,0) [0|1] "" Vector__XXX
SG_ cellVoltage_183_invalidFlag m45 : 15|1@0+ (1,0) [0|1] "" Vector__XXX
SG_ cellVoltage_180 m45 : 11|13@0+ (1,0) [0|8191] "mV" Vector__XXX
SG_ cell_voltage_181 m45 : 30|13@0+ (1,0) [0|8191] "mV" Vector__XXX
SG_ cell_voltage_182 m45 : 33|13@0+ (1,0) [0|8191] "mV" Vector__XXX
SG_ cell_voltage_183 m45 : 52|13@0+ (1,0) [0|8191] "mV" Vector__XXX
SG_ cellVoltage_184_invalidFlag m46 : 12|1@0+ (1,0) [0|1] "" Vector__XXX
SG_ cellVoltage_185_invalidFlag m46 : 13|1@0+ (1,0) [0|1] "" Vector__XXX
SG_ cellVoltage_186_invalidFlag m46 : 14|1@0+ (1,0) [0|1] "" Vector__XXX
SG_ cellVoltage_187_invalidFlag m46 : 15|1@0+ (1,0) [0|1] "" Vector__XXX
SG_ cellVoltage_184 m46 : 11|13@0+ (1,0) [0|8191] "mV" Vector__XXX
SG_ cell_voltage_185 m46 : 30|13@0+ (1,0) [0|8191] "mV" Vector__XXX
SG_ cell_voltage_186 m46 : 33|13@0+ (1,0) [0|8191] "mV" Vector__XXX
SG_ cell_voltage_187 m46 : 52|13@0+ (1,0) [0|8191] "mV" Vector__XXX
SG_ cellVoltage_188_invalidFlag m47 : 12|1@0+ (1,0) [0|1] "" Vector__XXX
SG_ cellVoltage_189_invalidFlag m47 : 13|1@0+ (1,0) [0|1] "" Vector__XXX
SG_ cellVoltage_190_invalidFlag m47 : 14|1@0+ (1,0) [0|1] "" Vector__XXX
SG_ cellVoltage_191_invalidFlag m47 : 15|1@0+ (1,0) [0|1] "" Vector__XXX
SG_ cellVoltage_188 m47 : 11|13@0+ (1,0) [0|8191] "mV" Vector__XXX
SG_ cell_voltage_189 m47 : 30|13@0+ (1,0) [0|8191] "mV" Vector__XXX
SG_ cell_voltage_190 m47 : 33|13@0+ (1,0) [0|8191] "mV" Vector__XXX
SG_ cell_voltage_191 m47 : 52|13@0+ (1,0) [0|8191] "mV" Vector__XXX
SG_ cellVoltage_192_invalidFlag m48 : 12|1@0+ (1,0) [0|1] "" Vector__XXX
SG_ cellVoltage_193_invalidFlag m48 : 13|1@0+ (1,0) [0|1] "" Vector__XXX
SG_ cellVoltage_194_invalidFlag m48 : 14|1@0+ (1,0) [0|1] "" Vector__XXX
SG_ cellVoltage_195_invalidFlag m48 : 15|1@0+ (1,0) [0|1] "" Vector__XXX
SG_ cellVoltage_192 m48 : 11|13@0+ (1,0) [0|8191] "mV" Vector__XXX
SG_ cell_voltage_193 m48 : 30|13@0+ (1,0) [0|8191] "mV" Vector__XXX
SG_ cell_voltage_194 m48 : 33|13@0+ (1,0) [0|8191] "mV" Vector__XXX
SG_ cell_voltage_195 m48 : 52|13@0+ (1,0) [0|8191] "mV" Vector__XXX
SG_ cellVoltage_196_invalidFlag m49 : 12|1@0+ (1,0) [0|1] "" Vector__XXX
SG_ cellVoltage_197_invalidFlag m49 : 13|1@0+ (1,0) [0|1] "" Vector__XXX
SG_ cellVoltage_198_invalidFlag m49 : 14|1@0+ (1,0) [0|1] "" Vector__XXX
SG_ cellVoltage_199_invalidFlag m49 : 15|1@0+ (1,0) [0|1] "" Vector__XXX
SG_ cellVoltage_196 m49 : 11|13@0+ (1,0) [0|8191] "mV" Vector__XXX
SG_ cell_voltage_197 m49 : 30|13@0+ (1,0) [0|8191] "mV" Vector__XXX
SG_ cell_voltage_198 m49 : 33|13@0+ (1,0) [0|8191] "mV" Vector__XXX
SG_ cell_voltage_199 m49 : 52|13@0+ (1,0) [0|8191] "mV" Vector__XXX
SG_ cellVoltage_200_invalidFlag m50 : 12|1@0+ (1,0) [0|1] "" Vector__XXX
SG_ cellVoltage_201_invalidFlag m50 : 13|1@0+ (1,0) [0|1] "" Vector__XXX
SG_ cellVoltage_202_invalidFlag m50 : 14|1@0+ (1,0) [0|1] "" Vector__XXX
SG_ cellVoltage_203_invalidFlag m50 : 15|1@0+ (1,0) [0|1] "" Vector__XXX
SG_ cellVoltage_200 m50 : 11|13@0+ (1,0) [0|8191] "mV" Vector__XXX
SG_ cell_voltage_201 m50 : 30|13@0+ (1,0) [0|8191] "mV" Vector__XXX
SG_ cell_voltage_202 m50 : 33|13@0+ (1,0) [0|8191] "mV" Vector__XXX
SG_ cell_voltage_203 m50 : 52|13@0+ (1,0) [0|8191] "mV" Vector__XXX
SG_ cellVoltage_204_invalidFlag m51 : 12|1@0+ (1,0) [0|1] "" Vector__XXX
SG_ cellVoltage_205_invalidFlag m51 : 13|1@0+ (1,0) [0|1] "" Vector__XXX
SG_ cellVoltage_206_invalidFlag m51 : 14|1@0+ (1,0) [0|1] "" Vector__XXX
SG_ cellVoltage_207_invalidFlag m51 : 15|1@0+ (1,0) [0|1] "" Vector__XXX
SG_ cellVoltage_204 m51 : 11|13@0+ (1,0) [0|8191] "mV" Vector__XXX
SG_ cell_voltage_205 m51 : 30|13@0+ (1,0) [0|8191] "mV" Vector__XXX
SG_ cell_voltage_206 m51 : 33|13@0+ (1,0) [0|8191] "mV" Vector__XXX
SG_ cell_voltage_207 m51 : 52|13@0+ (1,0) [0|8191] "mV" Vector__XXX
SG_ cellVoltage_208_invalidFlag m52 : 12|1@0+ (1,0) [0|1] "" Vector__XXX
SG_ cellVoltage_209_invalidFlag m52 : 13|1@0+ (1,0) [0|1] "" Vector__XXX
SG_ cellVoltage_210_invalidFlag m52 : 14|1@0+ (1,0) [0|1] "" Vector__XXX
SG_ cellVoltage_211_invalidFlag m52 : 15|1@0+ (1,0) [0|1] "" Vector__XXX
SG_ cellVoltage_208 m52 : 11|13@0+ (1,0) [0|8191] "mV" Vector__XXX
SG_ cell_voltage_209 m52 : 30|13@0+ (1,0) [0|8191] "mV" Vector__XXX
SG_ cell_voltage_210 m52 : 33|13@0+ (1,0) [0|8191] "mV" Vector__XXX
SG_ cell_voltage_211 m52 : 52|13@0+ (1,0) [0|8191] "mV" Vector__XXX
SG_ cellVoltage_212_invalidFlag m53 : 12|1@0+ (1,0) [0|1] "" Vector__XXX
SG_ cellVoltage_213_invalidFlag m53 : 13|1@0+ (1,0) [0|1] "" Vector__XXX
SG_ cellVoltage_214_invalidFlag m53 : 14|1@0+ (1,0) [0|1] "" Vector__XXX
SG_ cellVoltage_215_invalidFlag m53 : 15|1@0+ (1,0) [0|1] "" Vector__XXX
SG_ cellVoltage_212 m53 : 11|13@0+ (1,0) [0|8191] "mV" Vector__XXX
SG_ cell_voltage_213 m53 : 30|13@0+ (1,0) [0|8191] "mV" Vector__XXX
SG_ cell_voltage_214 m53 : 33|13@0+ (1,0) [0|8191] "mV" Vector__XXX
SG_ cell_voltage_215 m53 : 52|13@0+ (1,0) [0|8191] "mV" Vector__XXX

BO_ 592 foxBMS_CellTemperature: 8 Vector__XXX
SG_ foxBMS_CellTemperature_Mux M : 7|8@0+ (1,0) [0|0] "" Vector__XXX
SG_ cellTemperature_0_invalidFlag m0 : 8|1@0+ (1,0) [0|1] "" Vector__XXX
SG_ cellTemperature_1_invalidFlag m0 : 9|1@0+ (1,0) [0|1] "" Vector__XXX
SG_ cellTemperature_2_invalidFlag m0 : 10|1@0+ (1,0) [0|1] "" Vector__XXX
SG_ cellTemperature_3_invalidFlag m0 : 11|1@0+ (1,0) [0|1] "" Vector__XXX
SG_ cellTemperature_4_invalidFlag m0 : 12|1@0+ (1,0) [0|1] "" Vector__XXX
SG_ cellTemperature_5_invalidFlag m0 : 13|1@0+ (1,0) [0|1] "" Vector__XXX
SG_ cellTemperature_0 m0 : 23|8@0- (1,0) [-128|127] "degC" Vector__XXX
SG_ cellTemperature_1 m0 : 31|8@0- (1,0) [-128|127] "degC" Vector__XXX
SG_ cellTemperature_2 m0 : 39|8@0- (1,0) [-128|127] "degC" Vector__XXX
SG_ cellTemperature_3 m0 : 47|8@0- (1,0) [-128|127] "degC" Vector__XXX
SG_ cellTemperature_4 m0 : 55|8@0- (1,0) [-128|127] "degC" Vector__XXX
SG_ cellTemperature_5 m0 : 63|8@0- (1,0) [-128|127] "degC" Vector__XXX
SG_ cellTemperature_6_invalidFlag m1 : 8|1@0+ (1,0) [0|1] "" Vector__XXX
SG_ cellTemperature_7_invalidFlag m1 : 9|1@0+ (1,0) [0|1] "" Vector__XXX
SG_ cellTemperature_8_invalidFlag m1 : 10|1@0+ (1,0) [0|1] "" Vector__XXX
SG_ cellTemperature_9_invalidFlag m1 : 11|1@0+ (1,0) [0|1] "" Vector__XXX
SG_ cellTemperature_10_invalidFlag m1 : 12|1@0+ (1,0) [0|1] "" Vector__XXX
SG_ cellTemperature_11_invalidFlag m1 : 13|1@0+ (1,0) [0|1] "" Vector__XXX
SG_ cellTemperature_6 m1 : 23|8@0- (1,0) [-128|127] "degC" Vector__XXX
SG_ cellTemperature_7 m1 : 31|8@0- (1,0) [-128|127] "degC" Vector__XXX
SG_ cellTemperature_8 m1 : 39|8@0- (1,0) [-128|127] "degC" Vector__XXX
SG_ cellTemperature_9 m1 : 47|8@0- (1,0) [-128|127] "degC" Vector__XXX
SG_ cellTemperature_10 m1 : 55|8@0- (1,0) [-128|127] "degC" Vector__XXX
SG_ cellTemperature_11 m1 : 63|8@0- (1,0) [-128|127] "degC" Vector__XXX
SG_ cellTemperature_12_invalidFlag m2 : 8|1@0+ (1,0) [0|1] "" Vector__XXX
SG_ cellTemperature_13_invalidFlag m2 : 9|1@0+ (1,0) [0|1] "" Vector__XXX
SG_ cellTemperature_14_invalidFlag m2 : 10|1@0+ (1,0) [0|1] "" Vector__XXX
SG_ cellTemperature_15_invalidFlag m2 : 11|1@0+ (1,0) [0|1] "" Vector__XXX
SG_ cellTemperature_16_invalidFlag m2 : 12|1@0+ (1,0) [0|1] "" Vector__XXX
SG_ cellTemperature_17_invalidFlag m2 : 13|1@0+ (1,0) [0|1] "" Vector__XXX
SG_ cellTemperature_12 m2 : 23|8@0- (1,0) [-128|127] "degC" Vector__XXX
SG_ cellTemperature_13 m2 : 31|8@0- (1,0) [-128|127] "degC" Vector__XXX
SG_ cellTemperature_14 m2 : 39|8@0- (1,0) [-128|127] "degC" Vector__XXX
SG_ cellTemperature_15 m2 : 47|8@0- (1,0) [-128|127] "degC" Vector__XXX
SG_ cellTemperature_16 m2 : 55|8@0- (1,0) [-128|127] "degC" Vector__XXX
SG_ cellTemperature_17 m2 : 63|8@0- (1,0) [-128|127] "degC" Vector__XXX
SG_ cellTemperature_18_invalidFlag m3 : 8|1@0+ (1,0) [0|1] "" Vector__XXX
SG_ cellTemperature_19_invalidFlag m3 : 9|1@0+ (1,0) [0|1] "" Vector__XXX
SG_ cellTemperature_20_invalidFlag m3 : 10|1@0+ (1,0) [0|1] "" Vector__XXX
SG_ cellTemperature_21_invalidFlag m3 : 11|1@0+ (1,0) [0|1] "" Vector__XXX
SG_ cellTemperature_22_invalidFlag m3 : 12|1@0+ (1,0) [0|1] "" Vector__XXX
SG_ cellTemperature_23_invalidFlag m3 : 13|1@0+ (1,0) [0|1] "" Vector__XXX
SG_ cellTemperature_18 m3 : 23|8@0- (1,0) [-128|127] "degC" Vector__XXX
SG_ cellTemperature_19 m3 : 31|8@0- (1,0) [-128|127] "degC" Vector__XXX
SG_ cellTemperature_20 m3 : 39|8@0- (1,0) [-128|127] "degC" Vector__XXX
SG_ cellTemperature_21 m3 : 47|8@0- (1,0) [-128|127] "degC" Vector__XXX
SG_ cellTemperature_22 m3 : 55|8@0- (1,0) [-128|127] "degC" Vector__XXX
SG_ cellTemperature_23 m3 : 63|8@0- (1,0) [-128|127] "degC" Vector__XXX
SG_ cellTemperature_24_invalidFlag m4 : 8|1@0+ (1,0) [0|1] "" Vector__XXX
SG_ cellTemperature_25_invalidFlag m4 : 9|1@0+ (1,0) [0|1] "" Vector__XXX
SG_ cellTemperature_26_invalidFlag m4 : 10|1@0+ (1,0) [0|1] "" Vector__XXX
SG_ cellTemperature_27_invalidFlag m4 : 11|1@0+ (1,0) [0|1] "" Vector__XXX
SG_ cellTemperature_28_invalidFlag m4 : 12|1@0+ (1,0) [0|1] "" Vector__XXX
SG_ cellTemperature_29_invalidFlag m4 : 13|1@0+ (1,0) [0|1] "" Vector__XXX
SG_ cellTemperature_24 m4 : 23|8@0- (1,0) [-128|127] "degC" Vector__XXX
SG_ cellTemperature_25 m4 : 31|8@0- (1,0) [-128|127] "degC" Vector__XXX
SG_ cellTemperature_26 m4 : 39|8@0- (1,0) [-128|127] "degC" Vector__XXX
SG_ cellTemperature_27 m4 : 47|8@0- (1,0) [-128|127] "degC" Vector__XXX
SG_ cellTemperature_28 m4 : 55|8@0- (1,0) [-128|127] "degC" Vector__XXX
SG_ cellTemperature_29 m4 : 63|8@0- (1,0) [-128|127] "degC" Vector__XXX
SG_ cellTemperature_30_invalidFlag m5 : 8|1@0+ (1,0) [0|1] "" Vector__XXX
SG_ cellTemperature_31_invalidFlag m5 : 9|1@0+ (1,0) [0|1] "" Vector__XXX
SG_ cellTemperature_32_invalidFlag m5 : 10|1@0+ (1,0) [0|1] "" Vector__XXX
SG_ cellTemperature_33_invalidFlag m5 : 11|1@0+ (1,0) [0|1] "" Vector__XXX
SG_ cellTemperature_34_invalidFlag m5 : 12|1@0+ (1,0) [0|1] "" Vector__XXX
SG_ cellTemperature_35_invalidFlag m5 : 13|1@0+ (1,0) [0|1] "" Vector__XXX
SG_ cellTemperature_30 m5 : 23|8@0- (1,0) [-128|127] "degC" Vector__XXX
SG_ cellTemperature_31 m5 : 31|8@0- (1,0) [-128|127] "degC" Vector__XXX
SG_ cellTemperature_32 m5 : 39|8@0- (1,0) [-128|127] "degC" Vector__XXX
SG_ cellTemperature_33 m5 : 47|8@0- (1,0) [-128|127] "degC" Vector__XXX
SG_ cellTemperature_34 m5 : 55|8@0- (1,0) [-128|127] "degC" Vector__XXX
SG_ cellTemperature_35 m5 : 63|8@0- (1,0) [-128|127] "degC" Vector__XXX
SG_ cellTemperature_36_invalidFlag m6 : 8|1@0+ (1,0) [0|1] "" Vector__XXX
SG_ cellTemperature_37_invalidFlag m6 : 9|1@0+ (1,0) [0|1] "" Vector__XXX
SG_ cellTemperature_38_invalidFlag m6 : 10|1@0+ (1,0) [0|1] "" Vector__XXX
SG_ cellTemperature_39_invalidFlag m6 : 11|1@0+ (1,0) [0|1] "" Vector__XXX
SG_ cellTemperature_40_invalidFlag m6 : 12|1@0+ (1,0) [0|1] "" Vector__XXX
SG_ cellTemperature_41_invalidFlag m6 : 13|1@0+ (1,0) [0|1] "" Vector__XXX
SG_ cellTemperature_36 m6 : 23|8@0- (1,0) [-128|127] "degC" Vector__XXX
SG_ cellTemperature_37 m6 : 31|8@0- (1,0) [-128|127] "degC" Vector__XXX
SG_ cellTemperature_38 m6 : 39|8@0- (1,0) [-128|127] "degC" Vector__XXX
SG_ cellTemperature_39 m6 : 47|8@0- (1,0) [-128|127] "degC" Vector__XXX
SG_ cellTemperature_40 m6 : 55|8@0- (1,0) [-128|127] "degC" Vector__XXX
SG_ cellTemperature_41 m6 : 63|8@0- (1,0) [-128|127] "degC" Vector__XXX
SG_ cellTemperature_42_invalidFlag m7 : 8|1@0+ (1,0) [0|1] "" Vector__XXX
SG_ cellTemperature_43_invalidFlag m7 : 9|1@0+ (1,0) [0|1] "" Vector__XXX
SG_ cellTemperature_44_invalidFlag m7 : 10|1@0+ (1,0) [0|1] "" Vector__XXX
SG_ cellTemperature_45_invalidFlag m7 : 11|1@0+ (1,0) [0|1] "" Vector__XXX
SG_ cellTemperature_46_invalidFlag m7 : 12|1@0+ (1,0) [0|1] "" Vector__XXX
SG_ cellTemperature_47_invalidFlag m7 : 13|1@0+ (1,0) [0|1] "" Vector__XXX
SG_ cellTemperature_42 m7 : 23|8@0- (1,0) [-128|127] "degC" Vector__XXX
SG_ cellTemperature_43 m7 : 31|8@0- (1,0) [-128|127] "degC" Vector__XXX
SG_ cellTemperature_44 m7 : 39|8@0- (1,0) [-128|127] "degC" Vector__XXX
SG_ cellTemperature_45 m7 : 47|8@0- (1,0) [-128|127] "degC" Vector__XXX
SG_ cellTemperature_46 m7 : 55|8@0- (1,0) [-128|127] "degC" Vector__XXX
SG_ cellTemperature_47 m7 : 63|8@0- (1,0) [-128|127] "degC" Vector__XXX
SG_ cellTemperature_48_invalidFlag m8 : 8|1@0+ (1,0) [0|1] "" Vector__XXX
SG_ cellTemperature_49_invalidFlag m8 : 9|1@0+ (1,0) [0|1] "" Vector__XXX
SG_ cellTemperature_50_invalidFlag m8 : 10|1@0+ (1,0) [0|1] "" Vector__XXX
SG_ cellTemperature_51_invalidFlag m8 : 11|1@0+ (1,0) [0|1] "" Vector__XXX
SG_ cellTemperature_52_invalidFlag m8 : 12|1@0+ (1,0) [0|1] "" Vector__XXX
SG_ cellTemperature_53_invalidFlag m8 : 13|1@0+ (1,0) [0|1] "" Vector__XXX
SG_ cellTemperature_48 m8 : 23|8@0- (1,0) [-128|127] "degC" Vector__XXX
SG_ cellTemperature_49 m8 : 31|8@0- (1,0) [-128|127] "degC" Vector__XXX
SG_ cellTemperature_50 m8 : 39|8@0- (1,0) [-128|127] "degC" Vector__XXX
SG_ cellTemperature_51 m8 : 47|8@0- (1,0) [-128|127] "degC" Vector__XXX
SG_ cellTemperature_52 m8 : 55|8@0- (1,0) [-128|127] "degC" Vector__XXX
SG_ cellTemperature_53 m8 : 63|8@0- (1,0) [-128|127] "degC" Vector__XXX
SG_ cellTemperature_54_invalidFlag m9 : 8|1@0+ (1,0) [0|1] "" Vector__XXX
SG_ cellTemperature_55_invalidFlag m9 : 9|1@0+ (1,0) [0|1] "" Vector__XXX
SG_ cellTemperature_56_invalidFlag m9 : 10|1@0+ (1,0) [0|1] "" Vector__XXX
SG_ cellTemperature_57_invalidFlag m9 : 11|1@0+ (1,0) [0|1] "" Vector__XXX
SG_ cellTemperature_58_invalidFlag m9 : 12|1@0+ (1,0) [0|1] "" Vector__XXX
SG_ cellTemperature_59_invalidFlag m9 : 13|1@0+ (1,0) [0|1] "" Vector__XXX
SG_ cellTemperature_54 m9 : 23|8@0- (1,0) [-128|127] "degC" Vector__XXX
SG_ cellTemperature_55 m9 : 31|8@0- (1,0) [-128|127] "degC" Vector__XXX
SG_ cellTemperature_56 m9 : 39|8@0- (1,0) [-128|127] "degC" Vector__XXX
SG_ cellTemperature_57 m9 : 47|8@0- (1,0) [-128|127] "degC" Vector__XXX
SG_ cellTemperature_58 m9 : 55|8@0- (1,0) [-128|127] "degC" Vector__XXX
SG_ cellTemperature_59 m9 : 63|8@0- (1,0) [-128|127] "degC" Vector__XXX
SG_ cellTemperature_60_invalidFlag m10 : 8|1@0+ (1,0) [0|1] "" Vector__XXX
SG_ cellTemperature_61_invalidFlag m10 : 9|1@0+ (1,0) [0|1] "" Vector__XXX
SG_ cellTemperature_62_invalidFlag m10 : 10|1@0+ (1,0) [0|1] "" Vector__XXX
SG_ cellTemperature_63_invalidFlag m10 : 11|1@0+ (1,0) [0|1] "" Vector__XXX
SG_ cellTemperature_64_invalidFlag m10 : 12|1@0+ (1,0) [0|1] "" Vector__XXX
SG_ cellTemperature_65_invalidFlag m10 : 13|1@0+ (1,0) [0|1] "" Vector__XXX
SG_ cellTemperature_60 m10 : 23|8@0- (1,0) [-128|127] "degC" Vector__XXX
SG_ cellTemperature_61 m10 : 31|8@0- (1,0) [-128|127] "degC" Vector__XXX
SG_ cellTemperature_62 m10 : 39|8@0- (1,0) [-128|127] "degC" Vector__XXX
SG_ cellTemperature_63 m10 : 47|8@0- (1,0) [-128|127] "degC" Vector__XXX
SG_ cellTemperature_64 m10 : 55|8@0- (1,0) [-128|127] "degC" Vector__XXX
SG_ cellTemperature_65 m10 : 63|8@0- (1,0) [-128|127] "degC" Vector__XXX
SG_ cellTemperature_66_invalidFlag m11 : 8|1@0+ (1,0) [0|1] "" Vector__XXX
SG_ cellTemperature_67_invalidFlag m11 : 9|1@0+ (1,0) [0|1] "" Vector__XXX
SG_ cellTemperature_68_invalidFlag m11 : 10|1@0+ (1,0) [0|1] "" Vector__XXX
SG_ cellTemperature_69_invalidFlag m11 : 11|1@0+ (1,0) [0|1] "" Vector__XXX
SG_ cellTemperature_70_invalidFlag m11 : 12|1@0+ (1,0) [0|1] "" Vector__XXX
SG_ cellTemperature_71_invalidFlag m11 : 13|1@0+ (1,0) [0|1] "" Vector__XXX
SG_ cellTemperature_66 m11 : 23|8@0- (1,0) [-128|127] "degC" Vector__XXX
SG_ cellTemperature_67 m11 : 31|8@0- (1,0) [-128|127] "degC" Vector__XXX
SG_ cellTemperature_68 m11 : 39|8@0- (1,0) [-128|127] "degC" Vector__XXX
SG_ cellTemperature_69 m11 : 47|8@0- (1,0) [-128|127] "degC" Vector__XXX
SG_ cellTemperature_70 m11 : 55|8@0- (1,0) [-128|127] "degC" Vector__XXX
SG_ cellTemperature_71 m11 : 63|8@0- (1,0) [-128|127] "degC" Vector__XXX
SG_ cellTemperature_72_invalidFlag m12 : 8|1@0+ (1,0) [0|1] "" Vector__XXX
SG_ cellTemperature_73_invalidFlag m12 : 9|1@0+ (1,0) [0|1] "" Vector__XXX
SG_ cellTemperature_74_invalidFlag m12 : 10|1@0+ (1,0) [0|1] "" Vector__XXX
SG_ cellTemperature_75_invalidFlag m12 : 11|1@0+ (1,0) [0|1] "" Vector__XXX
SG_ cellTemperature_76_invalidFlag m12 : 12|1@0+ (1,0) [0|1] "" Vector__XXX
SG_ cellTemperature_77_invalidFlag m12 : 13|1@0+ (1,0) [0|1] "" Vector__XXX
SG_ cellTemperature_72 m12 : 23|8@0- (1,0) [-128|127] "degC" Vector__XXX
SG_ cellTemperature_73 m12 : 31|8@0- (1,0) [-128|127] "degC" Vector__XXX
SG_ cellTemperature_74 m12 : 39|8@0- (1,0) [-128|127] "degC" Vector__XXX
SG_ cellTemperature_75 m12 : 47|8@0- (1,0) [-128|127] "degC" Vector__XXX
SG_ cellTemperature_76 m12 : 55|8@0- (1,0) [-128|127] "degC" Vector__XXX
SG_ cellTemperature_77 m12 : 63|8@0- (1,0) [-128|127] "degC" Vector__XXX
SG_ cellTemperature_78_invalidFlag m13 : 8|1@0+ (1,0) [0|1] "" Vector__XXX
SG_ cellTemperature_79_invalidFlag m13 : 9|1@0+ (1,0) [0|1] "" Vector__XXX
SG_ cellTemperature_80_invalidFlag m13 : 10|1@0+ (1,0) [0|1] "" Vector__XXX
SG_ cellTemperature_81_invalidFlag m13 : 11|1@0+ (1,0) [0|1] "" Vector__XXX
SG_ cellTemperature_82_invalidFlag m13 : 12|1@0+ (1,0) [0|1] "" Vector__XXX
SG_ cellTemperature_83_invalidFlag m13 : 13|1@0+ (1,0) [0|1] "" Vector__XXX
SG_ cellTemperature_78 m13 : 23|8@0- (1,0) [-128|127] "degC" Vector__XXX
SG_ cellTemperature_79 m13 : 31|8@0- (1,0) [-128|127] "degC" Vector__XXX
SG_ cellTemperature_80 m13 : 39|8@0- (1,0) [-128|127] "degC" Vector__XXX
SG_ cellTemperature_81 m13 : 47|8@0- (1,0) [-128|127] "degC" Vector__XXX
SG_ cellTemperature_82 m13 : 55|8@0- (1,0) [-128|127] "degC" Vector__XXX
SG_ cellTemperature_83 m13 : 63|8@0- (1,0) [-128|127] "degC" Vector__XXX
SG_ cellTemperature_84_invalidFlag m14 : 8|1@0+ (1,0) [0|1] "" Vector__XXX
SG_ cellTemperature_85_invalidFlag m14 : 9|1@0+ (1,0) [0|1] "" Vector__XXX
SG_ cellTemperature_86_invalidFlag m14 : 10|1@0+ (1,0) [0|1] "" Vector__XXX
SG_ cellTemperature_87_invalidFlag m14 : 11|1@0+ (1,0) [0|1] "" Vector__XXX
SG_ cellTemperature_88_invalidFlag m14 : 12|1@0+ (1,0) [0|1] "" Vector__XXX
SG_ cellTemperature_89_invalidFlag m14 : 13|1@0+ (1,0) [0|1] "" Vector__XXX
SG_ cellTemperature_84 m14 : 23|8@0- (1,0) [-128|127] "degC" Vector__XXX
SG_ cellTemperature_85 m14 : 31|8@0- (1,0) [-128|127] "degC" Vector__XXX
SG_ cellTemperature_86 m14 : 39|8@0- (1,0) [-128|127] "degC" Vector__XXX
SG_ cellTemperature_87 m14 : 47|8@0- (1,0) [-128|127] "degC" Vector__XXX
SG_ cellTemperature_88 m14 : 55|8@0- (1,0) [-128|127] "degC" Vector__XXX
SG_ cellTemperature_89 m14 : 63|8@0- (1,0) [-128|127] "degC" Vector__XXX
SG_ cellTemperature_90_invalidFlag m15 : 8|1@0+ (1,0) [0|1] "" Vector__XXX
SG_ cellTemperature_91_invalidFlag m15 : 9|1@0+ (1,0) [0|1] "" Vector__XXX
SG_ cellTemperature_92_invalidFlag m15 : 10|1@0+ (1,0) [0|1] "" Vector__XXX
SG_ cellTemperature_93_invalidFlag m15 : 11|1@0+ (1,0) [0|1] "" Vector__XXX
SG_ cellTemperature_94_invalidFlag m15 : 12|1@0+ (1,0) [0|1] "" Vector__XXX
SG_ cellTemperature_95_invalidFlag m15 : 13|1@0+ (1,0) [0|1] "" Vector__XXX
SG_ cellTemperature_90 m15 : 23|8@0- (1,0) [-128|127] "degC" Vector__XXX
SG_ cellTemperature_91 m15 : 31|8@0- (1,0) [-128|127] "degC" Vector__XXX
SG_ cellTemperature_92 m15 : 39|8@0- (1,0) [-128|127] "degC" Vector__XXX
SG_ cellTemperature_93 m15 : 47|8@0- (1,0) [-128|127] "degC" Vector__XXX
SG_ cellTemperature_94 m15 : 55|8@0- (1,0) [-128|127] "degC" Vector__XXX
SG_ cellTemperature_95 m15 : 63|8@0- (1,0) [-128|127] "degC" Vector__XXX
SG_ cellTemperature_96_invalidFlag m16 : 8|1@0+ (1,0) [0|1] "" Vector__XXX
SG_ cellTemperature_97_invalidFlag m16 : 9|1@0+ (1,0) [0|1] "" Vector__XXX
SG_ cellTemperature_98_invalidFlag m16 : 10|1@0+ (1,0) [0|1] "" Vector__XXX
SG_ cellTemperature_99_invalidFlag m16 : 11|1@0+ (1,0) [0|1] "" Vector__XXX
SG_ cellTemperature_100_invalidFlag m16 : 12|1@0+ (1,0) [0|1] "" Vector__XXX
SG_ cellTemperature_101_invalidFlag m16 : 13|1@0+ (1,0) [0|1] "" Vector__XXX
SG_ cellTemperature_96 m16 : 23|8@0- (1,0) [-128|127] "degC" Vector__XXX
SG_ cellTemperature_97 m16 : 31|8@0- (1,0) [-128|127] "degC" Vector__XXX
SG_ cellTemperature_98 m16 : 39|8@0- (1,0) [-128|127] "degC" Vector__XXX
SG_ cellTemperature_99 m16 : 47|8@0- (1,0) [-128|127] "degC" Vector__XXX
SG_ cellTemperature_100 m16 : 55|8@0- (1,0) [-128|127] "degC" Vector__XXX
SG_ cellTemperature_101 m16 : 63|8@0- (1,0) [-128|127] "degC" Vector__XXX
SG_ cellTemperature_102_invalidFlag m17 : 8|1@0+ (1,0) [0|1] "" Vector__XXX
SG_ cellTemperature_103_invalidFlag m17 : 9|1@0+ (1,0) [0|1] "" Vector__XXX
SG_ cellTemperature_104_invalidFlag m17 : 10|1@0+ (1,0) [0|1] "" Vector__XXX
SG_ cellTemperature_105_invalidFlag m17 : 11|1@0+ (1,0) [0|1] "" Vector__XXX
SG_ cellTemperature_106_invalidFlag m17 : 12|1@0+ (1,0) [0|1] "" Vector__XXX
SG_ cellTemperature_107_invalidFlag m17 : 13|1@0+ (1,0) [0|1] "" Vector__XXX
SG_ cellTemperature_102 m17 : 23|8@0- (1,0) [-128|127] "degC" Vector__XXX
SG_ cellTemperature_103 m17 : 31|8@0- (1,0) [-128|127] "degC" Vector__XXX
SG_ cellTemperature_104 m17 : 39|8@0- (1,0) [-128|127] "degC" Vector__XXX
SG_ cellTemperature_105 m17 : 47|8@0- (1,0) [-128|127] "degC" Vector__XXX
SG_ cellTemperature_106 m17 : 55|8@0- (1,0) [-128|127] "degC" Vector__XXX
SG_ cellTemperature_107 m17 : 63|8@0- (1,0) [-128|127] "degC" Vector__XXX
SG_ cellTemperature_108_invalidFlag m18 : 8|1@0+ (1,0) [0|1] "" Vector__XXX
SG_ cellTemperature_109_invalidFlag m18 : 9|1@0+ (1,0) [0|1] "" Vector__XXX
SG_ cellTemperature_110_invalidFlag m18 : 10|1@0+ (1,0) [0|1] "" Vector__XXX
SG_ cellTemperature_111_invalidFlag m18 : 11|1@0+ (1,0) [0|1] "" Vector__XXX
SG_ cellTemperature_112_invalidFlag m18 : 12|1@0+ (1,0) [0|1] "" Vector__XXX
SG_ cellTemperature_113_invalidFlag m18 : 13|1@0+ (1,0) [0|1] "" Vector__XXX
SG_ cellTemperature_108 m18 : 23|8@0- (1,0) [-128|127] "degC" Vector__XXX
SG_ cellTemperature_109 m18 : 31|8@0- (1,0) [-128|127] "degC" Vector__XXX
SG_ cellTemperature_110 m18 : 39|8@0- (1,0) [-128|127] "degC" Vector__XXX
SG_ cellTemperature_111 m18 : 47|8@0- (1,0) [-128|127] "degC" Vector__XXX
SG_ cellTemperature_112 m18 : 55|8@0- (1,0) [-128|127] "degC" Vector__XXX
SG_ cellTemperature_113 m18 : 63|8@0- (1,0) [-128|127] "degC" Vector__XXX
SG_ cellTemperature_114_invalidFlag m19 : 8|1@0+ (1,0) [0|1] "" Vector__XXX
SG_ cellTemperature_115_invalidFlag m19 : 9|1@0+ (1,0) [0|1] "" Vector__XXX
SG_ cellTemperature_116_invalidFlag m19 : 10|1@0+ (1,0) [0|1] "" Vector__XXX
SG_ cellTemperature_117_invalidFlag m19 : 11|1@0+ (1,0) [0|1] "" Vector__XXX
SG_ cellTemperature_118_invalidFlag m19 : 12|1@0+ (1,0) [0|1] "" Vector__XXX
SG_ cellTemperature_119_invalidFlag m19 : 13|1@0+ (1,0) [0|1] "" Vector__XXX
SG_ cellTemperature_114 m19 : 23|8@0- (1,0) [-128|127] "degC" Vector__XXX
SG_ cellTemperature_115 m19 : 31|8@0- (1,0) [-128|127] "degC" Vector__XXX
SG_ cellTemperature_116 m19 : 39|8@0- (1,0) [-128|127] "degC" Vector__XXX
SG_ cellTemperature_117 m19 : 47|8@0- (1,0) [-128|127] "degC" Vector__XXX
SG_ cellTemperature_118 m19 : 55|8@0- (1,0) [-128|127] "degC" Vector__XXX
SG_ cellTemperature_119 m19 : 63|8@0- (1,0) [-128|127] "degC" Vector__XXX
SG_ cellTemperature_120_invalidFlag m20 : 8|1@0+ (1,0) [0|1] "" Vector__XXX
SG_ cellTemperature_121_invalidFlag m20 : 9|1@0+ (1,0) [0|1] "" Vector__XXX
SG_ cellTemperature_122_invalidFlag m20 : 10|1@0+ (1,0) [0|1] "" Vector__XXX
SG_ cellTemperature_123_invalidFlag m20 : 11|1@0+ (1,0) [0|1] "" Vector__XXX
SG_ cellTemperature_124_invalidFlag m20 : 12|1@0+ (1,0) [0|1] "" Vector__XXX
SG_ cellTemperature_125_invalidFlag m20 : 13|1@0+ (1,0) [0|1] "" Vector__XXX
SG_ cellTemperature_120 m20 : 23|8@0- (1,0) [-128|127] "degC" Vector__XXX
SG_ cellTemperature_121 m20 : 31|8@0- (1,0) [-128|127] "degC" Vector__XXX
SG_ cellTemperature_122 m20 : 39|8@0- (1,0) [-128|127] "degC" Vector__XXX
SG_ cellTemperature_123 m20 : 47|8@0- (1,0) [-128|127] "degC" Vector__XXX
SG_ cellTemperature_124 m20 : 55|8@0- (1,0) [-128|127] "degC" Vector__XXX
SG_ cellTemperature_125 m20 : 63|8@0- (1,0) [-128|127] "degC" Vector__XXX
SG_ cellTemperature_126_invalidFlag m21 : 8|1@0+ (1,0) [0|1] "" Vector__XXX
SG_ cellTemperature_127_invalidFlag m21 : 9|1@0+ (1,0) [0|1] "" Vector__XXX
SG_ cellTemperature_128_invalidFlag m21 : 10|1@0+ (1,0) [0|1] "" Vector__XXX
SG_ cellTemperature_129_invalidFlag m21 : 11|1@0+ (1,0) [0|1] "" Vector__XXX
SG_ cellTemperature_130_invalidFlag m21 : 12|1@0+ (1,0) [0|1] "" Vector__XXX
SG_ cellTemperature_131_invalidFlag m21 : 13|1@0+ (1,0) [0|1] "" Vector__XXX
SG_ cellTemperature_126 m21 : 23|8@0- (1,0) [-128|127] "degC" Vector__XXX
SG_ cellTemperature_127 m21 : 31|8@0- (1,0) [-128|127] "degC" Vector__XXX
SG_ cellTemperature_128 m21 : 39|8@0- (1,0) [-128|127] "degC" Vector__XXX
SG_ cellTemperature_129 m21 : 47|8@0- (1,0) [-128|127] "degC" Vector__XXX
SG_ cellTemperature_130 m21 : 55|8@0- (1,0) [-128|127] "degC" Vector__XXX
SG_ cellTemperature_131 m21 : 63|8@0- (1,0) [-128|127] "degC" Vector__XXX
SG_ cellTemperature_132_invalidFlag m22 : 8|1@0+ (1,0) [0|1] "" Vector__XXX
SG_ cellTemperature_133_invalidFlag m22 : 9|1@0+ (1,0) [0|1] "" Vector__XXX
SG_ cellTemperature_134_invalidFlag m22 : 10|1@0+ (1,0) [0|1] "" Vector__XXX
SG_ cellTemperature_135_invalidFlag m22 : 11|1@0+ (1,0) [0|1] "" Vector__XXX
SG_ cellTemperature_136_invalidFlag m22 : 12|1@0+ (1,0) [0|1] "" Vector__XXX
SG_ cellTemperature_137_invalidFlag m22 : 13|1@0+ (1,0) [0|1] "" Vector__XXX
SG_ cellTemperature_132 m22 : 23|8@0- (1,0) [-128|127] "degC" Vector__XXX
SG_ cellTemperature_133 m22 : 31|8@0- (1,0) [-128|127] "degC" Vector__XXX
SG_ cellTemperature_134 m22 : 39|8@0- (1,0) [-128|127] "degC" Vector__XXX
SG_ cellTemperature_135 m22 : 47|8@0- (1,0) [-128|127] "degC" Vector__XXX
SG_ cellTemperature_136 m22 : 55|8@0- (1,0) [-128|127] "degC" Vector__XXX
SG_ cellTemperature_137 m22 : 63|8@0- (1,0) [-128|127] "degC" Vector__XXX
SG_ cellTemperature_138_invalidFlag m23 : 8|1@0+ (1,0) [0|1] "" Vector__XXX
SG_ cellTemperature_139_invalidFlag m23 : 9|1@0+ (1,0) [0|1] "" Vector__XXX
SG_ cellTemperature_140_invalidFlag m23 : 10|1@0+ (1,0) [0|1] "" Vector__XXX
SG_ cellTemperature_141_invalidFlag m23 : 11|1@0+ (1,0) [0|1] "" Vector__XXX
SG_ cellTemperature_142_invalidFlag m23 : 12|1@0+ (1,0) [0|1] "" Vector__XXX
SG_ cellTemperature_143_invalidFlag m23 : 13|1@0+ (1,0) [0|1] "" Vector__XXX
SG_ cellTemperature_138 m23 : 23|8@0- (1,0) [-128|127] "degC" Vector__XXX
SG_ cellTemperature_139 m23 : 31|8@0- (1,0) [-128|127] "degC" Vector__XXX
SG_ cellTemperature_140 m23 : 39|8@0- (1,0) [-128|127] "degC" Vector__XXX
SG_ cellTemperature_141 m23 : 47|8@0- (1,0) [-128|127] "degC" Vector__XXX
SG_ cellTemperature_142 m23 : 55|8@0- (1,0) [-128|127] "degC" Vector__XXX
SG_ cellTemperature_143 m23 : 63|8@0- (1,0) [-128|127] "degC" Vector__XXX
SG_ cellTemperature_144_invalidFlag m24 : 8|1@0+ (1,0) [0|1] "" Vector__XXX
SG_ cellTemperature_145_invalidFlag m24 : 9|1@0+ (1,0) [0|1] "" Vector__XXX
SG_ cellTemperature_146_invalidFlag m24 : 10|1@0+ (1,0) [0|1] "" Vector__XXX
SG_ cellTemperature_147_invalidFlag m24 : 11|1@0+ (1,0) [0|1] "" Vector__XXX
SG_ cellTemperature_148_invalidFlag m24 : 12|1@0+ (1,0) [0|1] "" Vector__XXX
SG_ cellTemperature_149_invalidFlag m24 : 13|1@0+ (1,0) [0|1] "" Vector__XXX
SG_ cellTemperature_144 m24 : 23|8@0- (1,0) [-128|127] "degC" Vector__XXX
SG_ cellTemperature_145 m24 : 31|8@0- (1,0) [-128|127] "degC" Vector__XXX
SG_ cellTemperature_146 m24 : 39|8@0- (1,0) [-128|127] "degC" Vector__XXX
SG_ cellTemperature_147 m24 : 47|8@0- (1,0) [-128|127] "degC" Vector__XXX
SG_ cellTemperature_148 m24 : 55|8@0- (1,0) [-128|127] "degC" Vector__XXX
SG_ cellTemperature_149 m24 : 63|8@0- (1,0) [-128|127] "degC" Vector__XXX
SG_ cellTemperature_150_invalidFlag m25 : 8|1@0+ (1,0) [0|1] "" Vector__XXX
SG_ cellTemperature_151_invalidFlag m25 : 9|1@0+ (1,0) [0|1] "" Vector__XXX
SG_ cellTemperature_152_invalidFlag m25 : 10|1@0+ (1,0) [0|1] "" Vector__XXX
SG_ cellTemperature_153_invalidFlag m25 : 11|1@0+ (1,0) [0|1] "" Vector__XXX
SG_ cellTemperature_154_invalidFlag m25 : 12|1@0+ (1,0) [0|1] "" Vector__XXX
SG_ cellTemperature_155_invalidFlag m25 : 13|1@0+ (1,0) [0|1] "" Vector__XXX
SG_ cellTemperature_150 m25 : 23|8@0- (1,0) [-128|127] "degC" Vector__XXX
SG_ cellTemperature_151 m25 : 31|8@0- (1,0) [-128|127] "degC" Vector__XXX
SG_ cellTemperature_152 m25 : 39|8@0- (1,0) [-128|127] "degC" Vector__XXX
SG_ cellTemperature_153 m25 : 47|8@0- (1,0) [-128|127] "degC" Vector__XXX
SG_ cellTemperature_154 m25 : 55|8@0- (1,0) [-128|127] "degC" Vector__XXX
SG_ cellTemperature_155 m25 : 63|8@0- (1,0) [-128|127] "degC" Vector__XXX
SG_ cellTemperature_156_invalidFlag m26 : 8|1@0+ (1,0) [0|1] "" Vector__XXX
SG_ cellTemperature_157_invalidFlag m26 : 9|1@0+ (1,0) [0|1] "" Vector__XXX
SG_ cellTemperature_158_invalidFlag m26 : 10|1@0+ (1,0) [0|1] "" Vector__XXX
SG_ cellTemperature_159_invalidFlag m26 : 11|1@0+ (1,0) [0|1] "" Vector__XXX
SG_ cellTemperature_160_invalidFlag m26 : 12|1@0+ (1,0) [0|1] "" Vector__XXX
SG_ cellTemperature_161_invalidFlag m26 : 13|1@0+ (1,0) [0|1] "" Vector__XXX
SG_ cellTemperature_156 m26 : 23|8@0- (1,0) [-128|127] "degC" Vector__XXX
SG_ cellTemperature_157 m26 : 31|8@0- (1,0) [-128|127] "degC" Vector__XXX
SG_ cellTemperature_158 m26 : 39|8@0- (1,0) [-128|127] "degC" Vector__XXX
SG_ cellTemperature_159 m26 : 47|8@0- (1,0) [-128|127] "degC" Vector__XXX
SG_ cellTemperature_160 m26 : 55|8@0- (1,0) [-128|127] "degC" Vector__XXX
SG_ cellTemperature_161 m26 : 63|8@0- (1,0) [-128|127] "degC" Vector__XXX
SG_ cellTemperature_162_invalidFlag m27 : 8|1@0+ (1,0) [0|1] "" Vector__XXX
SG_ cellTemperature_163_invalidFlag m27 : 9|1@0+ (1,0) [0|1] "" Vector__XXX
SG_ cellTemperature_164_invalidFlag m27 : 10|1@0+ (1,0) [0|1] "" Vector__XXX
SG_ cellTemperature_165_invalidFlag m27 : 11|1@0+ (1,0) [0|1] "" Vector__XXX
SG_ cellTemperature_166_invalidFlag m27 : 12|1@0+ (1,0) [0|1] "" Vector__XXX
SG_ cellTemperature_167_invalidFlag m27 : 13|1@0+ (1,0) [0|1] "" Vector__XXX
SG_ cellTemperature_162 m27 : 23|8@0- (1,0) [-128|127] "degC" Vector__XXX
SG_ cellTemperature_163 m27 : 31|8@0- (1,0) [-128|127] "degC" Vector__XXX
SG_ cellTemperature_164 m27 : 39|8@0- (1,0) [-128|127] "degC" Vector__XXX
SG_ cellTemperature_165 m27 : 47|8@0- (1,0) [-128|127] "degC" Vector__XXX
SG_ cellTemperature_166 m27 : 55|8@0- (1,0) [-128|127] "degC" Vector__XXX
SG_ cellTemperature_167 m27 : 63|8@0- (1,0) [-128|127] "degC" Vector__XXX
SG_ cellTemperature_168_invalidFlag m28 : 8|1@0+ (1,0) [0|1] "" Vector__XXX
SG_ cellTemperature_169_invalidFlag m28 : 9|1@0+ (1,0) [0|1] "" Vector__XXX
SG_ cellTemperature_170_invalidFlag m28 : 10|1@0+ (1,0) [0|1] "" Vector__XXX
SG_ cellTemperature_171_invalidFlag m28 : 11|1@0+ (1,0) [0|1] "" Vector__XXX
SG_ cellTemperature_172_invalidFlag m28 : 12|1@0+ (1,0) [0|1] "" Vector__XXX
SG_ cellTemperature_173_invalidFlag m28 : 13|1@0+ (1,0) [0|1] "" Vector__XXX
SG_ cellTemperature_168 m28 : 23|8@0- (1,0) [-128|127] "degC" Vector__XXX
SG_ cellTemperature_169 m28 : 31|8@0- (1,0) [-128|127] "degC" Vector__XXX
SG_ cellTemperature_170 m28 : 39|8@0- (1,0) [-128|127] "degC" Vector__XXX
SG_ cellTemperature_171 m28 : 47|8@0- (1,0) [-128|127] "degC" Vector__XXX
SG_ cellTemperature_172 m28 : 55|8@0- (1,0) [-128|127] "degC" Vector__XXX
SG_ cellTemperature_173 m28 : 63|8@0- (1,0) [-128|127] "degC" Vector__XXX
SG_ cellTemperature_174_invalidFlag m29 : 8|1@0+ (1,0) [0|1] "" Vector__XXX
SG_ cellTemperature_175_invalidFlag m29 : 9|1@0+ (1,0) [0|1] "" Vector__XXX
SG_ cellTemperature_176_invalidFlag m29 : 10|1@0+ (1,0) [0|1] "" Vector__XXX
SG_ cellTemperature_177_invalidFlag m29 : 11|1@0+ (1,0) [0|1] "" Vector__XXX
SG_ cellTemperature_178_invalidFlag m29 : 12|1@0+ (1,0) [0|1] "" Vector__XXX
SG_ cellTemperature_179_invalidFlag m29 : 13|1@0+ (1,0) [0|1] "" Vector__XXX
SG_ cellTemperature_174 m29 : 23|8@0- (1,0) [-128|127] "degC" Vector__XXX
SG_ cellTemperature_175 m29 : 31|8@0- (1,0) [-128|127] "degC" Vector__XXX
SG_ cellTemperature_176 m29 : 39|8@0- (1,0) [-128|127] "degC" Vector__XXX
SG_ cellTemperature_177 m29 : 47|8@0- (1,0) [-128|127] "degC" Vector__XXX
SG_ cellTemperature_178 m29 : 55|8@0- (1,0) [-128|127] "degC" Vector__XXX
SG_ cellTemperature_179 m29 : 63|8@0- (1,0) [-128|127] "degC" Vector__XXX

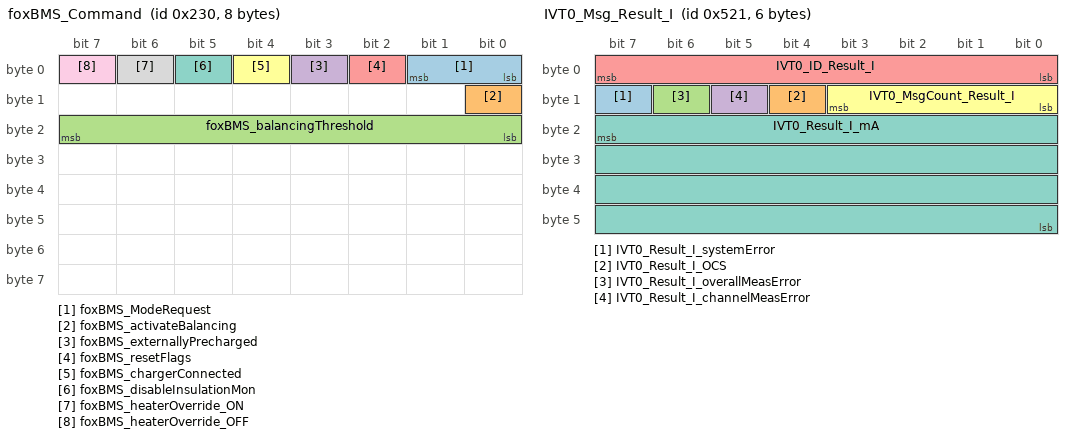
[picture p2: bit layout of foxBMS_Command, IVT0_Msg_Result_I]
BO_ 560 foxBMS_Command: 8 Vector__XXX
SG_ foxBMS_ModeRequest : 1|2@0+ (1,0) [0|3] "" Vector__XXX
SG_ foxBMS_activateBalancing : 8|1@0+ (1,0) [0|1] "" Vector__XXX
SG_ foxBMS_balancingThreshold : 23|8@0+ (1,0) [0|255] "mV" Vector__XXX
SG_ foxBMS_externallyPrecharged : 3|1@0+ (1,0) [0|1] "" Vector__XXX
SG_ foxBMS_resetFlags : 2|1@1+ (1,0) [0|1] "" Vector__XXX
SG_ foxBMS_chargerConnected : 4|1@1+ (1,0) [0|1] "" Vector__XXX
SG_ foxBMS_disableInsulationMon : 5|1@1+ (1,0) [0|1] "" Vector__XXX
SG_ foxBMS_heaterOverride_ON : 6|1@1+ (1,0) [0|1] "" Vector__XXX
SG_ foxBMS_heaterOverride_OFF : 7|1@1+ (1,0) [0|1] "" Vector__XXX

BO_ 544 foxBMS_State: 8 Vector__XXX
SG_ foxBMS_State : 3|4@0+ (1,0) [0|15] "" Vector__XXX
SG_ BMS_nrOfConnectedStrings : 7|4@0+ (1,0) [0|15] "" Vector__XXX
SG_ foxBMS_generalError : 10|1@0+ (1,0) [0|1] "" Vector__XXX
SG_ foxBMS_generalWarning : 9|1@0+ (1,0) [0|1] "" Vector__XXX
SG_ foxBMS_Error_dieTemperatureMCU : 18|1@0+ (1,0) [0|1] "" Vector__XXX
SG_ foxBMS_Error_OvertempPCB : 19|1@0+ (1,0) [0|1] "" Vector__XXX
SG_ foxBMS_Error_UndertempPCB : 20|1@0+ (1,0) [0|1] "" Vector__XXX
SG_ foxBMS_Error_PrechargeVolt : 16|1@0+ (1,0) [0|1] "" Vector__XXX
SG_ foxBMS_Error_PrechargeCurrent : 17|1@0+ (1,0) [0|1] "" Vector__XXX
SG_ foxBMS_heaterState : 14|1@0+ (1,0) [0|1] "" Vector__XXX
SG_ foxBMS_coolingState : 15|1@0+ (1,0) [0|1] "" Vector__XXX
SG_ foxBMS_insulationMonitoring : 13|1@0+ (1,0) [0|1] "" Vector__XXX
SG_ foxBMS_chargingComplete : 8|1@0+ (1,0) [0|1] "" Vector__XXX
SG_ foxBMS_EmergencyShutoff : 11|1@1+ (1,0) [0|1] "" Vector__XXX
SG_ foxBMS_MainFuseBlown : 21|1@0+ (1,0) [0|1] "" Vector__XXX
SG_ foxBMS_insulationResistance : 63|8@0+ (10,0) [0|2550] "kOhm" Vector__XXX
SG_ foxBMS_Error_Interlock : 22|1@1+ (1,0) [0|1] "" Vector__XXX
SG_ foxBMS_NrDeactivatedStrings : 51|4@0+ (1,0) [0|15] "" Vector__XXX

BO_ 545 foxBMS_StringState: 8 Vector__XXX
SG_ foxBMS_StringState_Mux M : 3|4@0+ (1,0) [0|0] "" Vector__XXX
SG_ String0_stringConnected m0 : 4|1@0+ (1,0) [0|1] "" Vector__XXX
SG_ String0_balancing_active m0 : 5|1@0+ (1,0) [0|1] "" Vector__XXX
SG_ String0_Err_overtemp_charge m0 : 8|1@0+ (1,0) [0|1] "" Vector__XXX
SG_ String0_Err_undertemp_charge m0 : 9|1@0+ (1,0) [0|1] "" Vector__XXX
SG_ String0_Err_overtemp_discharge m0 : 10|1@0+ (1,0) [0|1] "" Vector__XXX
SG_ String0_Err_undertemp_discharge m0 : 11|1@0+ (1,0) [0|1] "" Vector__XXX
SG_ String0_Err_Overcurrent_charge m0 : 12|1@0+ (1,0) [0|1] "" Vector__XXX
SG_ String0_Err_Overcurre_discharge m0 : 13|1@0+ (1,0) [0|1] "" Vector__XXX
SG_ String0_Err_Overvoltage m0 : 14|1@0+ (1,0) [0|1] "" Vector__XXX
SG_ String0_Err_Undervoltage m0 : 15|1@0+ (1,0) [0|1] "" Vector__XXX
SG_ String0_Err_deep_discharge m0 : 7|1@0+ (1,0) [0|1] "" Vector__XXX
SG_ String0_Err_CS_currentMeas m0 : 43|1@0+ (1,0) [0|1] "" Vector__XXX
SG_ String0_Err_positiveContactor m0 : 32|1@0+ (1,0) [0|1] "" Vector__XXX
SG_ String0_Err_openWire m0 : 49|1@0+ (1,0) [0|1] "" Vector__XXX
SG_ String0_openWireNumber m0 : 63|8@0+ (1,0) [0|255] "" Vector__XXX
SG_ String0_Err_plaus_cell_volt m0 : 52|1@0+ (1,0) [0|1] "" Vector__XXX
SG_ String0_Err_plaus_cell_temp m0 : 51|1@0+ (1,0) [0|1] "" Vector__XXX
SG_ String0_Err_plaus_string_volt m0 : 53|1@0+ (1,0) [0|1] "" Vector__XXX
SG_ String0_Err_slave_hardware m0 : 34|1@0+ (1,0) [0|1] "" Vector__XXX
SG_ String0_Err_dsyChainPrim_Comm m0 : 35|1@0+ (1,0) [0|1] "" Vector__XXX
SG_ String0_Err_dsyChainPrim_CRC m0 : 37|1@0+ (1,0) [0|1] "" Vector__XXX
SG_ String0_Err_dsyChainRedun_Comm m0 : 36|1@0+ (1,0) [0|1] "" Vector__XXX
SG_ String0_Err_dsyChainRedun_CRC m0 : 38|1@0+ (1,0) [0|1] "" Vector__XXX
SG_ String0_Err_dsyPrim_voltMeasOor m0 : 39|1@0+ (1,0) [0|1] "" Vector__XXX
SG_ String0_Err_dsyRedun_voltMeasOor m0 : 40|1@0+ (1,0) [0|1] "" Vector__XXX
SG_ String0_Err_dsyPrim_tempMeasOor m0 : 41|1@0+ (1,0) [0|1] "" Vector__XXX
SG_ String0_Err_dsyRedun_tempMeasOor m0 : 42|1@0+ (1,0) [0|1] "" Vector__XXX
SG_ String0_Err_CS_coulombCountMeas m0 : 44|1@0+ (1,0) [0|1] "" Vector__XXX
SG_ String0_Err_CS_energyCountMeas m0 : 45|1@0+ (1,0) [0|1] "" Vector__XXX
SG_ String0_Err_plaus_volt_spread m0 : 55|1@0+ (1,0) [0|1] "" Vector__XXX
SG_ String0_Err_plaus_temp_spread m0 : 54|1@0+ (1,0) [0|1] "" Vector__XXX
SG_ String0_fuseBlown m0 : 6|1@1+ (1,0) [0|1] "" Vector__XXX
SG_ String0_Warning_overvoltage_MOL m0 : 22|1@1+ (1,0) [0|1] "" Vector__XXX
SG_ String0_Warning_undervoltage_MOL m0 : 23|1@1+ (1,0) [0|1] "" Vector__XXX
SG_ String0_Wrng_chargeOverTemp_MOL m0 : 16|1@1+ (1,0) [0|1] "" Vector__XXX
SG_ String0_Wrng_dischrgOverTemp_MOL m0 : 18|1@1+ (1,0) [0|1] "" Vector__XXX
SG_ String0_Wrng_chargeUnderTemp_MOL m0 : 17|1@1+ (1,0) [0|1] "" Vector__XXX
SG_ String0_Wrng_dischrgUnderTmp_MOL m0 : 19|1@1+ (1,0) [0|1] "" Vector__XXX
SG_ String0_Wrng_chargeOverCur_MOL m0 : 20|1@1+ (1,0) [0|1] "" Vector__XXX
SG_ String0_Wrng_dischargOverCur_MOL m0 : 21|1@1+ (1,0) [0|1] "" Vector__XXX
SG_ String0_Wrng_chargeOverTemp_RSL m0 : 24|1@1+ (1,0) [0|1] "" Vector__XXX
SG_ String0_Wrng_chargeUnderTemp_RSL m0 : 25|1@1+ (1,0) [0|1] "" Vector__XXX
SG_ String0_Wrng_dischrgOverTemp_RSL m0 : 26|1@1+ (1,0) [0|1] "" Vector__XXX
SG_ String0_Wrng_dischrgUnderTmp_RSL m0 : 27|1@1+ (1,0) [0|1] "" Vector__XXX
SG_ String0_Wrng_chargeOverCur_RSL m0 : 28|1@1+ (1,0) [0|1] "" Vector__XXX
SG_ String0_Wrng_dischargOverCur_RSL m0 : 29|1@1+ (1,0) [0|1] "" Vector__XXX
SG_ String0_Wrng_overvoltage_RSL m0 : 30|1@1+ (1,0) [0|1] "" Vector__XXX
SG_ String0_Wrng_undervoltage_RSL m0 : 31|1@1+ (1,0) [0|1] "" Vector__XXX
SG_ String0_Err_negativeContactor m0 : 33|1@1+ (1,0) [0|1] "" Vector__XXX
SG_ String0_Err_CS_voltage1Meas m0 : 46|1@1+ (1,0) [0|1] "" Vector__XXX
SG_ String0_Err_CS_voltage2Meas m0 : 47|1@1+ (1,0) [0|1] "" Vector__XXX
SG_ String0_Err_CS_voltage3Meas m0 : 48|1@1+ (1,0) [0|1] "" Vector__XXX
SG_ String1_stringConnected m1 : 4|1@0+ (1,0) [0|1] "" Vector__XXX
SG_ String1_balancing_active m1 : 5|1@0+ (1,0) [0|1] "" Vector__XXX
SG_ String1_Err_overtemp_charge m1 : 8|1@0+ (1,0) [0|1] "" Vector__XXX
SG_ String1_Err_undertemp_charge m1 : 9|1@0+ (1,0) [0|1] "" Vector__XXX
SG_ String1_Err_overtemp_discharge m1 : 10|1@0+ (1,0) [0|1] "" Vector__XXX
SG_ String1_Err_undertemp_discharge m1 : 11|1@0+ (1,0) [0|1] "" Vector__XXX
SG_ String1_Err_Overcurrent_charge m1 : 12|1@0+ (1,0) [0|1] "" Vector__XXX
SG_ String1_Err_Overcurre_discharge m1 : 13|1@0+ (1,0) [0|1] "" Vector__XXX
SG_ String1_Err_Overvoltage m1 : 14|1@0+ (1,0) [0|1] "" Vector__XXX
SG_ String1_Err_Undervoltage m1 : 15|1@0+ (1,0) [0|1] "" Vector__XXX
SG_ String1_Err_deep_discharge m1 : 7|1@0+ (1,0) [0|1] "" Vector__XXX
SG_ String1_Err_CS_currentMeas m1 : 43|1@0+ (1,0) [0|1] "" Vector__XXX
SG_ String1_Err_positiveContactor m1 : 32|1@0+ (1,0) [0|1] "" Vector__XXX
SG_ String1_Err_openWire m1 : 49|1@0+ (1,0) [0|1] "" Vector__XXX
SG_ String1_openWireNumber m1 : 63|8@0+ (1,0) [0|255] "" Vector__XXX
SG_ String1_Err_plaus_cell_volt m1 : 52|1@0+ (1,0) [0|1] "" Vector__XXX
SG_ String1_Err_plaus_cell_temp m1 : 51|1@0+ (1,0) [0|1] "" Vector__XXX
SG_ String1_Err_plaus_string_volt m1 : 53|1@0+ (1,0) [0|1] "" Vector__XXX
SG_ String1_Err_slave_hardware m1 : 34|1@0+ (1,0) [0|1] "" Vector__XXX
SG_ String1_Err_dsyChainPrim_Comm m1 : 35|1@0+ (1,0) [0|1] "" Vector__XXX
SG_ String1_Err_dsyChainPrim_CRC m1 : 37|1@0+ (1,0) [0|1] "" Vector__XXX
SG_ String1_Err_dsyChainRedun_Comm m1 : 36|1@0+ (1,0) [0|1] "" Vector__XXX
SG_ String1_Err_dsyChainRedun_CRC m1 : 38|1@0+ (1,0) [0|1] "" Vector__XXX
SG_ String1_Err_dsyPrim_voltMeasOor m1 : 39|1@0+ (1,0) [0|1] "" Vector__XXX
SG_ String1_Err_dsyRedun_voltMeasOor m1 : 40|1@0+ (1,0) [0|1] "" Vector__XXX
SG_ String1_Err_dsyPrim_tempMeasOor m1 : 41|1@0+ (1,0) [0|1] "" Vector__XXX
SG_ String1_Err_dsyRedun_tempMeasOor m1 : 42|1@0+ (1,0) [0|1] "" Vector__XXX
SG_ String1_Err_CS_coulombCountMeas m1 : 44|1@0+ (1,0) [0|1] "" Vector__XXX
SG_ String1_Err_CS_energyCountMeas m1 : 45|1@0+ (1,0) [0|1] "" Vector__XXX
SG_ String1_Err_plaus_volt_spread m1 : 55|1@0+ (1,0) [0|1] "" Vector__XXX
SG_ String1_Err_plaus_temp_spread m1 : 54|1@0+ (1,0) [0|1] "" Vector__XXX
SG_ String1_fuseBlown m1 : 6|1@1+ (1,0) [0|1] "" Vector__XXX
SG_ String1_Warning_overvoltage_MOL m1 : 22|1@1+ (1,0) [0|1] "" Vector__XXX
SG_ String1_Warning_undervoltage_MOL m1 : 23|1@1+ (1,0) [0|1] "" Vector__XXX
SG_ String1_Wrng_chargeOverTemp_MOL m1 : 16|1@1+ (1,0) [0|1] "" Vector__XXX
SG_ String1_Wrng_dischrgOverTemp_MOL m1 : 18|1@1+ (1,0) [0|1] "" Vector__XXX
SG_ String1_Wrng_chargeUnderTemp_MOL m1 : 17|1@1+ (1,0) [0|1] "" Vector__XXX
SG_ String1_Wrng_dischrgUnderTmp_MOL m1 : 19|1@1+ (1,0) [0|1] "" Vector__XXX
SG_ String1_Wrng_chargeOverCur_MOL m1 : 20|1@1+ (1,0) [0|1] "" Vector__XXX
SG_ String1_Wrng_dischargOverCur_MOL m1 : 21|1@1+ (1,0) [0|1] "" Vector__XXX
SG_ String1_Wrng_chargeOverTemp_RSL m1 : 24|1@1+ (1,0) [0|1] "" Vector__XXX
SG_ String1_Wrng_chargeUnderTemp_RSL m1 : 25|1@1+ (1,0) [0|1] "" Vector__XXX
SG_ String1_Wrng_dischrgOverTemp_RSL m1 : 26|1@1+ (1,0) [0|1] "" Vector__XXX
SG_ String1_Wrng_dischrgUnderTmp_RSL m1 : 27|1@1+ (1,0) [0|1] "" Vector__XXX
SG_ String1_Wrng_chargeOverCur_RSL m1 : 28|1@1+ (1,0) [0|1] "" Vector__XXX
SG_ String1_Wrng_dischargOverCur_RSL m1 : 29|1@1+ (1,0) [0|1] "" Vector__XXX
SG_ String1_Wrng_overvoltage_RSL m1 : 30|1@1+ (1,0) [0|1] "" Vector__XXX
SG_ String1_Wrng_undervoltage_RSL m1 : 31|1@1+ (1,0) [0|1] "" Vector__XXX
SG_ String1_Err_negativeContactor m1 : 33|1@1+ (1,0) [0|1] "" Vector__XXX
SG_ String1_Err_CS_voltage1Meas m1 : 46|1@1+ (1,0) [0|1] "" Vector__XXX
SG_ String1_Err_CS_voltage2Meas m1 : 47|1@1+ (1,0) [0|1] "" Vector__XXX
SG_ String1_Err_CS_voltage3Meas m1 : 48|1@1+ (1,0) [0|1] "" Vector__XXX
SG_ String2_stringConnected m2 : 4|1@0+ (1,0) [0|1] "" Vector__XXX
SG_ String2_balancing_active m2 : 5|1@0+ (1,0) [0|1] "" Vector__XXX
SG_ String2_Err_overtemp_charge m2 : 8|1@0+ (1,0) [0|1] "" Vector__XXX
SG_ String2_Err_undertemp_charge m2 : 9|1@0+ (1,0) [0|1] "" Vector__XXX
SG_ String2_Err_overtemp_discharge m2 : 10|1@0+ (1,0) [0|1] "" Vector__XXX
SG_ String2_Err_undertemp_discharge m2 : 11|1@0+ (1,0) [0|1] "" Vector__XXX
SG_ String2_Err_Overcurrent_charge m2 : 12|1@0+ (1,0) [0|1] "" Vector__XXX
SG_ String2_Err_Overcurre_discharge m2 : 13|1@0+ (1,0) [0|1] "" Vector__XXX
SG_ String2_Err_Overvoltage m2 : 14|1@0+ (1,0) [0|1] "" Vector__XXX
SG_ String2_Err_Undervoltage m2 : 15|1@0+ (1,0) [0|1] "" Vector__XXX
SG_ String2_Err_deep_discharge m2 : 7|1@0+ (1,0) [0|1] "" Vector__XXX
SG_ String2_Err_CS_currentMeas m2 : 43|1@0+ (1,0) [0|1] "" Vector__XXX
SG_ String2_Err_positiveContactor m2 : 32|1@0+ (1,0) [0|1] "" Vector__XXX
SG_ String2_Err_openWire m2 : 49|1@0+ (1,0) [0|1] "" Vector__XXX
SG_ String2_openWireNumber m2 : 63|8@0+ (1,0) [0|255] "" Vector__XXX
SG_ String2_Err_plaus_cell_volt m2 : 52|1@0+ (1,0) [0|1] "" Vector__XXX
SG_ String2_Err_plaus_cell_temp m2 : 51|1@0+ (1,0) [0|1] "" Vector__XXX
SG_ String2_Err_plaus_string_volt m2 : 53|1@0+ (1,0) [0|1] "" Vector__XXX
SG_ String2_Err_slave_hardware m2 : 34|1@0+ (1,0) [0|1] "" Vector__XXX
SG_ String2_Err_dsyChainPrim_Comm m2 : 35|1@0+ (1,0) [0|1] "" Vector__XXX
SG_ String2_Err_dsyChainPrim_CRC m2 : 37|1@0+ (1,0) [0|1] "" Vector__XXX
SG_ String2_Err_dsyChainRedun_Comm m2 : 36|1@0+ (1,0) [0|1] "" Vector__XXX
SG_ String2_Err_dsyChainRedun_CRC m2 : 38|1@0+ (1,0) [0|1] "" Vector__XXX
SG_ String2_Err_dsyPrim_voltMeasOor m2 : 39|1@0+ (1,0) [0|1] "" Vector__XXX
SG_ String2_Err_dsyRedun_voltMeasOor m2 : 40|1@0+ (1,0) [0|1] "" Vector__XXX
SG_ String2_Err_dsyPrim_tempMeasOor m2 : 41|1@0+ (1,0) [0|1] "" Vector__XXX
SG_ String2_Err_dsyRedun_tempMeasOor m2 : 42|1@0+ (1,0) [0|1] "" Vector__XXX
SG_ String2_Err_CS_coulombCountMeas m2 : 44|1@0+ (1,0) [0|1] "" Vector__XXX
SG_ String2_Err_CS_energyCountMeas m2 : 45|1@0+ (1,0) [0|1] "" Vector__XXX
SG_ String2_Err_plaus_volt_spread m2 : 55|1@0+ (1,0) [0|1] "" Vector__XXX
SG_ String2_Err_plaus_temp_spread m2 : 54|1@0+ (1,0) [0|1] "" Vector__XXX
SG_ String2_fuseBlown m2 : 6|1@1+ (1,0) [0|1] "" Vector__XXX
SG_ String2_Warning_overvoltage_MOL m2 : 22|1@1+ (1,0) [0|1] "" Vector__XXX
SG_ String2_Warning_undervoltage_MOL m2 : 23|1@1+ (1,0) [0|1] "" Vector__XXX
SG_ String2_Wrng_chargeOverTemp_MOL m2 : 16|1@1+ (1,0) [0|1] "" Vector__XXX
SG_ String2_Wrng_dischrgOverTemp_MOL m2 : 18|1@1+ (1,0) [0|1] "" Vector__XXX
SG_ String2_Wrng_chargeUnderTemp_MOL m2 : 17|1@1+ (1,0) [0|1] "" Vector__XXX
SG_ String2_Wrng_dischrgUnderTmp_MOL m2 : 19|1@1+ (1,0) [0|1] "" Vector__XXX
SG_ String2_Wrng_chargeOverCur_MOL m2 : 20|1@1+ (1,0) [0|1] "" Vector__XXX
SG_ String2_Wrng_dischargOverCur_MOL m2 : 21|1@1+ (1,0) [0|1] "" Vector__XXX
SG_ String2_Wrng_chargeOverTemp_RSL m2 : 24|1@1+ (1,0) [0|1] "" Vector__XXX
SG_ String2_Wrng_chargeUnderTemp_RSL m2 : 25|1@1+ (1,0) [0|1] "" Vector__XXX
SG_ String2_Wrng_dischrgOverTemp_RSL m2 : 26|1@1+ (1,0) [0|1] "" Vector__XXX
SG_ String2_Wrng_dischrgUnderTmp_RSL m2 : 27|1@1+ (1,0) [0|1] "" Vector__XXX
SG_ String2_Wrng_chargeOverCur_RSL m2 : 28|1@1+ (1,0) [0|1] "" Vector__XXX
SG_ String2_Wrng_dischargOverCur_RSL m2 : 29|1@1+ (1,0) [0|1] "" Vector__XXX
SG_ String2_Wrng_overvoltage_RSL m2 : 30|1@1+ (1,0) [0|1] "" Vector__XXX
SG_ String2_Wrng_undervoltage_RSL m2 : 31|1@1+ (1,0) [0|1] "" Vector__XXX
SG_ String2_Err_negativeContactor m2 : 33|1@1+ (1,0) [0|1] "" Vector__XXX
SG_ String2_Err_CS_voltage1Meas m2 : 46|1@1+ (1,0) [0|1] "" Vector__XXX
SG_ String2_Err_CS_voltage2Meas m2 : 47|1@1+ (1,0) [0|1] "" Vector__XXX
SG_ String2_Err_CS_voltage3Meas m2 : 48|1@1+ (1,0) [0|1] "" Vector__XXX

BO_ 641 foxBMS_StringMinimumMaximumValues: 8 Vector__XXX
SG_ foxBMS_StringMinimumMaximumValues_Mux M : 3|4@0+ (1,0) [0|0] "" Vector__XXX
SG_ String0_minimumCellVoltage m0 : 18|13@0+ (1,0) [0|8191] "mV" Vector__XXX
SG_ String0_maximumCellVoltage m0 : 15|13@0+ (1,0) [0|8191] "mV" Vector__XXX
SG_ String0_maximumCellTemperature m0 : 37|9@0- (0.5,0) [-128|127.5] "degC" Vector__XXX
SG_ String0_minimumCellTemperature m0 : 44|9@0- (0.5,0) [-128|127.5] "degC" Vector__XXX
SG_ String1_minimumCellVoltage m1 : 18|13@0+ (1,0) [0|8191] "mV" Vector__XXX
SG_ String1_maximumCellVoltage m1 : 15|13@0+ (1,0) [0|8191] "mV" Vector__XXX
SG_ String1_maximumCellTemperature m1 : 37|9@0- (0.5,0) [-128|127.5] "degC" Vector__XXX
SG_ String1_minimumCellTemperature m1 : 44|9@0- (0.5,0) [-128|127.5] "degC" Vector__XXX
SG_ String2_minimumCellVoltage m2 : 18|13@0+ (1,0) [0|8191] "mV" Vector__XXX
SG_ String2_maximumCellVoltage m2 : 15|13@0+ (1,0) [0|8191] "mV" Vector__XXX
SG_ String2_maximumCellTemperature m2 : 37|9@0- (0.5,0) [-128|127.5] "degC" Vector__XXX
SG_ String2_minimumCellTemperature m2 : 44|9@0- (0.5,0) [-128|127.5] "degC" Vector__XXX

BO_ 642 foxBMS_StringStateEstimation: 8 Vector__XXX
SG_ foxBMS_StringStateEstimation_Mux M : 7|4@0+ (1,0) [0|0] "" Vector__XXX
SG_ String0_minimumSOC m0 : 3|9@0+ (0.25,0) [0|127.75] "%" Vector__XXX
SG_ String0_averageSOC m0 : 10|9@0+ (0.25,0) [0|127.5] "%" Vector__XXX
SG_ String0_maximumSOC m0 : 17|8@0+ (0.25,0) [0|63.75] "%" Vector__XXX
SG_ String0_SOE m0 : 25|9@0+ (0.25,0) [0|127.5] "%" Vector__XXX
SG_ String0_Energy_Wh m0 : 55|16@0+ (0.01,0) [0|655.35] "kWh" Vector__XXX
SG_ String0_SOH m0 : 32|9@0+ (0.25,0) [0|127.5] "" Vector__XXX
SG_ String1_minimumSOC m1 : 3|9@0+ (0.25,0) [0|127.75] "%" Vector__XXX
SG_ String1_averageSOC m1 : 10|9@0+ (0.25,0) [0|127.5] "%" Vector__XXX
SG_ String1_maximumSOC m1 : 17|8@0+ (0.25,0) [0|63.75] "%" Vector__XXX
SG_ String1_SOE m1 : 25|9@0+ (0.25,0) [0|127.5] "%" Vector__XXX
SG_ String1_Energy_Wh m1 : 55|16@0+ (0.01,0) [0|655.35] "kWh" Vector__XXX
SG_ String1_SOH m1 : 32|9@0+ (0.25,0) [0|127.5] "" Vector__XXX
SG_ String2_minimumSOC m2 : 3|9@0+ (0.25,0) [0|127.75] "%" Vector__XXX
SG_ String2_averageSOC m2 : 10|9@0+ (0.25,0) [0|127.5] "%" Vector__XXX
SG_ String2_maximumSOC m2 : 17|8@0+ (0.25,0) [0|63.75] "%" Vector__XXX
SG_ String2_SOE m2 : 25|9@0+ (0.25,0) [0|127.5] "%" Vector__XXX
SG_ String2_Energy_Wh m2 : 55|16@0+ (0.01,0) [0|655.35] "kWh" Vector__XXX
SG_ String2_SOH m2 : 32|9@0+ (0.25,0) [0|127.5] "" Vector__XXX

BO_ 512 foxBMS_Debug: 8 Vector__XXX

BO_ 1313 IVT0_Msg_Result_I: 6 Vector__XXX
SG_ IVT0_Result_I_systemError : 15|1@0+ (1,0) [0|1] "" Vector__XXX
SG_ IVT0_Result_I_OCS : 12|1@0+ (1,0) [0|1] "" Vector__XXX
SG_ IVT0_Result_I_overallMeasError : 14|1@0+ (1,0) [0|1] "" Vector__XXX
SG_ IVT0_Result_I_channelMeasError : 13|1@0+ (1,0) [0|1] "" Vector__XXX
SG_ IVT0_ID_Result_I : 7|8@0+ (1,0) [0|255] "" Vector__XXX
SG_ IVT0_MsgCount_Result_I : 11|4@0+ (1,0) [0|15] "" Vector__XXX
SG_ IVT0_Result_I_mA : 23|32@0- (1,0) [-2147483648|2147483647] "mA" Vector__XXX

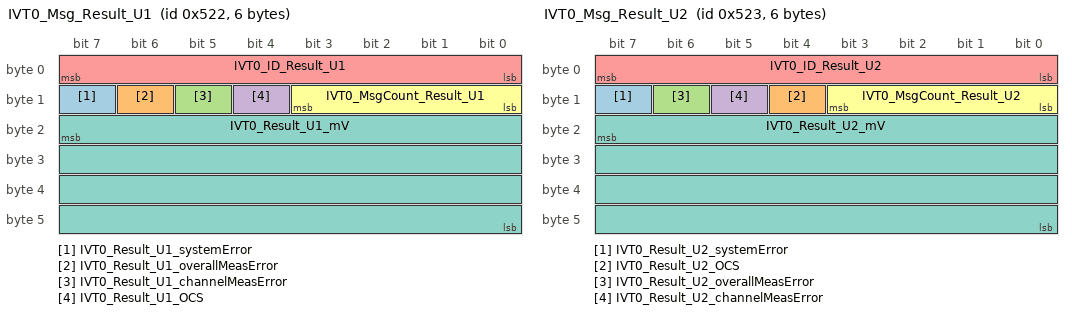
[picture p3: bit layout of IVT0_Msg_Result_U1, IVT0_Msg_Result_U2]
BO_ 1314 IVT0_Msg_Result_U1: 6 Vector__XXX
SG_ IVT0_Result_U1_systemError : 15|1@0+ (1,0) [0|1] "" Vector__XXX
SG_ IVT0_Result_U1_overallMeasError : 14|1@0+ (1,0) [0|1] "" Vector__XXX
SG_ IVT0_Result_U1_channelMeasError : 13|1@0+ (1,0) [0|1] "" Vector__XXX
SG_ IVT0_Result_U1_OCS : 12|1@0+ (1,0) [0|1] "" Vector__XXX
SG_ IVT0_ID_Result_U1 : 7|8@0+ (1,0) [1|1] "" Vector__XXX
SG_ IVT0_MsgCount_Result_U1 : 11|4@0+ (1,0) [0|15] "" Vector__XXX
SG_ IVT0_Result_U1_mV : 23|32@0- (1,0) [-2147483648|2147483647] "mV" Vector__XXX

BO_ 1315 IVT0_Msg_Result_U2: 6 Vector__XXX
SG_ IVT0_Result_U2_systemError : 15|1@0+ (1,0) [0|1] "" Vector__XXX
SG_ IVT0_Result_U2_OCS : 12|1@0+ (1,0) [0|1] "" Vector__XXX
SG_ IVT0_Result_U2_overallMeasError : 14|1@0+ (1,0) [0|1] "" Vector__XXX
SG_ IVT0_Result_U2_channelMeasError : 13|1@0+ (1,0) [0|1] "" Vector__XXX
SG_ IVT0_ID_Result_U2 : 7|8@0+ (1,0) [2|2] "" Vector__XXX
SG_ IVT0_MsgCount_Result_U2 : 11|4@0+ (1,0) [0|15] "" Vector__XXX
SG_ IVT0_Result_U2_mV : 23|32@0- (1,0) [-2147483648|2147483647] "mV" Vector__XXX

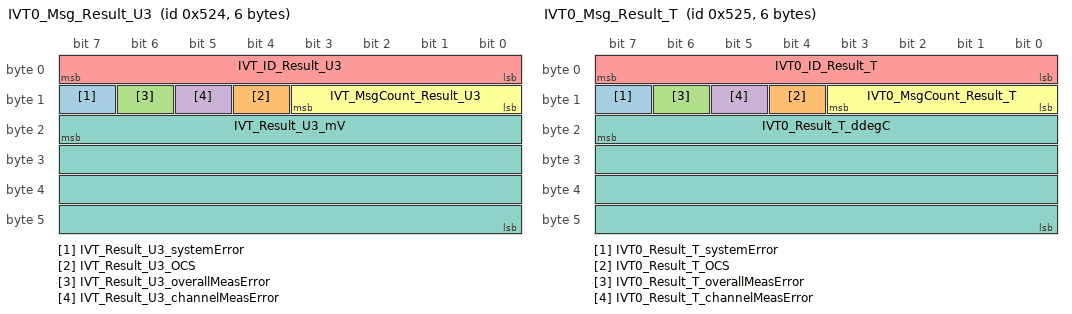
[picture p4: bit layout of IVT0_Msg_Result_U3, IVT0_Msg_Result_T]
BO_ 1316 IVT0_Msg_Result_U3: 6 Vector__XXX
SG_ IVT_Result_U3_systemError : 15|1@0+ (1,0) [0|1] "" Vector__XXX
SG_ IVT_Result_U3_OCS : 12|1@0+ (1,0) [0|1] "" Vector__XXX
SG_ IVT_Result_U3_overallMeasError : 14|1@0+ (1,0) [0|1] "" Vector__XXX
SG_ IVT_Result_U3_channelMeasError : 13|1@0+ (1,0) [0|1] "" Vector__XXX
SG_ IVT_ID_Result_U3 : 7|8@0+ (1,0) [3|3] "" Vector__XXX
SG_ IVT_MsgCount_Result_U3 : 11|4@0+ (1,0) [0|15] "" Vector__XXX
SG_ IVT_Result_U3_mV : 23|32@0- (1,0) [-2147483648|2147483647] "mV" Vector__XXX

BO_ 1317 IVT0_Msg_Result_T: 6 Vector__XXX
SG_ IVT0_Result_T_systemError : 15|1@0+ (1,0) [0|1] "" Vector__XXX
SG_ IVT0_Result_T_OCS : 12|1@0+ (1,0) [0|1] "" Vector__XXX
SG_ IVT0_Result_T_overallMeasError : 14|1@0+ (1,0) [0|1] "" Vector__XXX
SG_ IVT0_Result_T_channelMeasError : 13|1@0+ (1,0) [0|1] "" Vector__XXX
SG_ IVT0_ID_Result_T : 7|8@0+ (1,0) [4|4] "" Vector__XXX
SG_ IVT0_MsgCount_Result_T : 11|4@0+ (1,0) [0|15] "" Vector__XXX
SG_ IVT0_Result_T_ddegC : 23|32@0- (0.1,0) [-214748364.8|214748364.7] "ddegCC" Vector__XXX

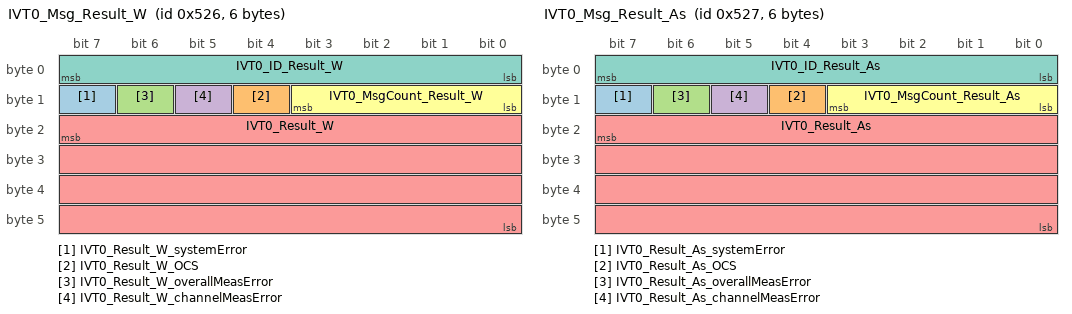
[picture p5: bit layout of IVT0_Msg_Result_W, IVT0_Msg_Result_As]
BO_ 1318 IVT0_Msg_Result_W: 6 Vector__XXX
SG_ IVT0_Result_W_systemError : 15|1@0+ (1,0) [0|1] "" Vector__XXX
SG_ IVT0_Result_W_OCS : 12|1@0+ (1,0) [0|1] "" Vector__XXX
SG_ IVT0_Result_W_overallMeasError : 14|1@0+ (1,0) [0|1] "" Vector__XXX
SG_ IVT0_Result_W_channelMeasError : 13|1@0+ (1,0) [0|1] "" Vector__XXX
SG_ IVT0_Result_W : 23|32@0- (1,0) [-2147483648|2147483647] "W" Vector__XXX
SG_ IVT0_MsgCount_Result_W : 11|4@0+ (1,0) [0|15] "" Vector__XXX
SG_ IVT0_ID_Result_W : 7|8@0+ (1,0) [5|5] "" Vector__XXX

BO_ 1319 IVT0_Msg_Result_As: 6 Vector__XXX
SG_ IVT0_Result_As_systemError : 15|1@0+ (1,0) [0|1] "" Vector__XXX
SG_ IVT0_Result_As_OCS : 12|1@0+ (1,0) [0|1] "" Vector__XXX
SG_ IVT0_Result_As_overallMeasError : 14|1@0+ (1,0) [0|1] "" Vector__XXX
SG_ IVT0_Result_As_channelMeasError : 13|1@0+ (1,0) [0|1] "" Vector__XXX
SG_ IVT0_Result_As : 23|32@0- (1,0) [-2147483648|2147483647] "As" Vector__XXX
SG_ IVT0_MsgCount_Result_As : 11|4@0+ (1,0) [0|15] "" Vector__XXX
SG_ IVT0_ID_Result_As : 7|8@0+ (1,0) [6|6] "" Vector__XXX

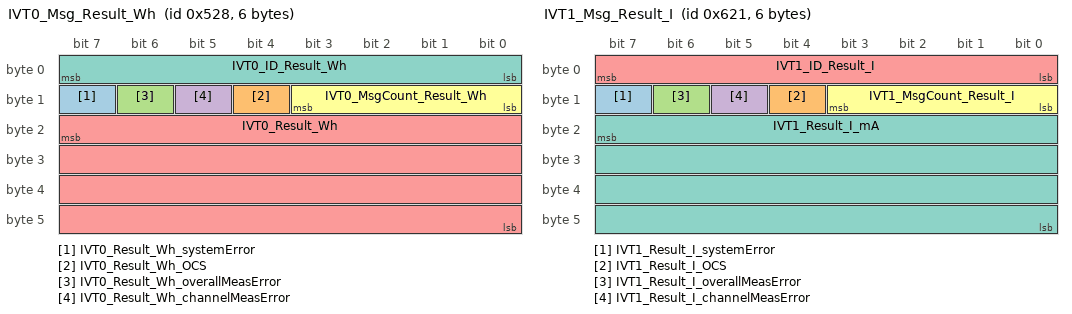
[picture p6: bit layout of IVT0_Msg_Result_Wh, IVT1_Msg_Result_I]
BO_ 1320 IVT0_Msg_Result_Wh: 6 Vector__XXX
SG_ IVT0_Result_Wh_systemError : 15|1@0+ (1,0) [0|1] "" Vector__XXX
SG_ IVT0_Result_Wh_OCS : 12|1@0+ (1,0) [0|1] "" Vector__XXX
SG_ IVT0_Result_Wh_overallMeasError : 14|1@0+ (1,0) [0|1] "" Vector__XXX
SG_ IVT0_Result_Wh_channelMeasError : 13|1@0+ (1,0) [0|1] "" Vector__XXX
SG_ IVT0_Result_Wh : 23|32@0- (1,0) [-2147483648|2147483647] "Wh" Vector__XXX
SG_ IVT0_MsgCount_Result_Wh : 11|4@0+ (1,0) [0|15] "" Vector__XXX
SG_ IVT0_ID_Result_Wh : 7|8@0+ (1,0) [7|7] "" Vector__XXX

BO_ 1569 IVT1_Msg_Result_I: 6 Vector__XXX
SG_ IVT1_Result_I_systemError : 15|1@0+ (1,0) [0|1] "" Vector__XXX
SG_ IVT1_Result_I_OCS : 12|1@0+ (1,0) [0|1] "" Vector__XXX
SG_ IVT1_Result_I_overallMeasError : 14|1@0+ (1,0) [0|1] "" Vector__XXX
SG_ IVT1_Result_I_channelMeasError : 13|1@0+ (1,0) [0|1] "" Vector__XXX
SG_ IVT1_ID_Result_I : 7|8@0+ (1,0) [0|255] "" Vector__XXX
SG_ IVT1_MsgCount_Result_I : 11|4@0+ (1,0) [0|15] "" Vector__XXX
SG_ IVT1_Result_I_mA : 23|32@0- (1,0) [-2147483648|2147483647] "mA" Vector__XXX

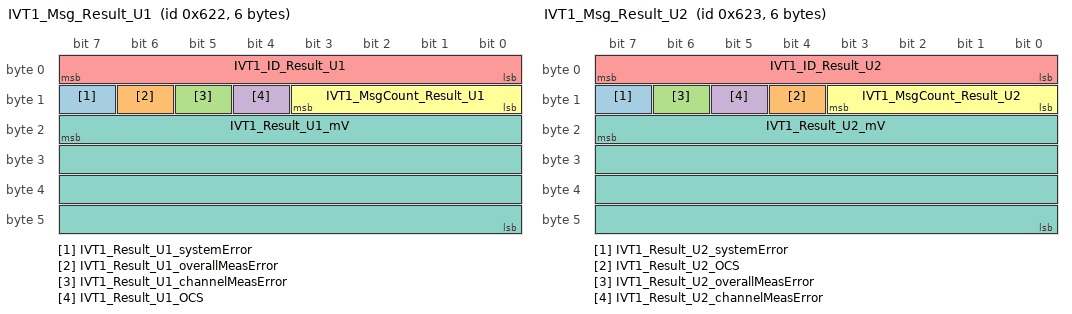
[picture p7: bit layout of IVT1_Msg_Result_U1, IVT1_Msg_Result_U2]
BO_ 1570 IVT1_Msg_Result_U1: 6 Vector__XXX
SG_ IVT1_Result_U1_systemError : 15|1@0+ (1,0) [0|1] "" Vector__XXX
SG_ IVT1_Result_U1_overallMeasError : 14|1@0+ (1,0) [0|1] "" Vector__XXX
SG_ IVT1_Result_U1_channelMeasError : 13|1@0+ (1,0) [0|1] "" Vector__XXX
SG_ IVT1_Result_U1_OCS : 12|1@0+ (1,0) [0|1] "" Vector__XXX
SG_ IVT1_ID_Result_U1 : 7|8@0+ (1,0) [1|1] "" Vector__XXX
SG_ IVT1_MsgCount_Result_U1 : 11|4@0+ (1,0) [0|15] "" Vector__XXX
SG_ IVT1_Result_U1_mV : 23|32@0- (1,0) [-2147483648|2147483647] "mV" Vector__XXX

BO_ 1571 IVT1_Msg_Result_U2: 6 Vector__XXX
SG_ IVT1_Result_U2_systemError : 15|1@0+ (1,0) [0|1] "" Vector__XXX
SG_ IVT1_Result_U2_OCS : 12|1@0+ (1,0) [0|1] "" Vector__XXX
SG_ IVT1_Result_U2_overallMeasError : 14|1@0+ (1,0) [0|1] "" Vector__XXX
SG_ IVT1_Result_U2_channelMeasError : 13|1@0+ (1,0) [0|1] "" Vector__XXX
SG_ IVT1_ID_Result_U2 : 7|8@0+ (1,0) [2|2] "" Vector__XXX
SG_ IVT1_MsgCount_Result_U2 : 11|4@0+ (1,0) [0|15] "" Vector__XXX
SG_ IVT1_Result_U2_mV : 23|32@0- (1,0) [-2147483648|2147483647] "mV" Vector__XXX

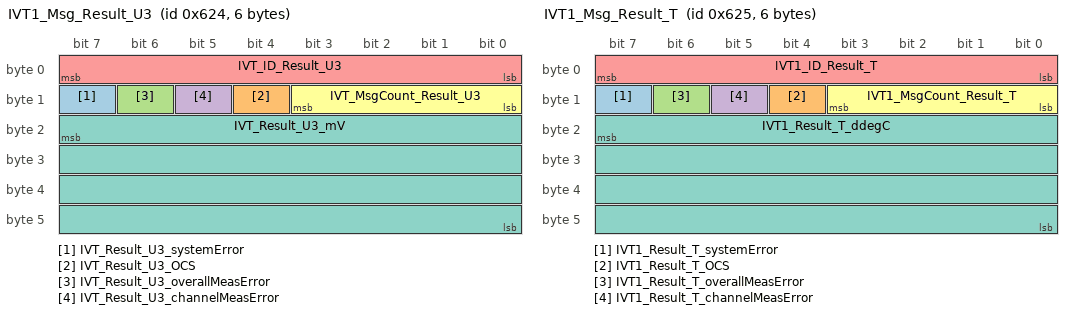
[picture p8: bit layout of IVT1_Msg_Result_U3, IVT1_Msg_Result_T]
BO_ 1572 IVT1_Msg_Result_U3: 6 Vector__XXX
SG_ IVT_Result_U3_systemError : 15|1@0+ (1,0) [0|1] "" Vector__XXX
SG_ IVT_Result_U3_OCS : 12|1@0+ (1,0) [0|1] "" Vector__XXX
SG_ IVT_Result_U3_overallMeasError : 14|1@0+ (1,0) [0|1] "" Vector__XXX
SG_ IVT_Result_U3_channelMeasError : 13|1@0+ (1,0) [0|1] "" Vector__XXX
SG_ IVT_ID_Result_U3 : 7|8@0+ (1,0) [3|3] "" Vector__XXX
SG_ IVT_MsgCount_Result_U3 : 11|4@0+ (1,0) [0|15] "" Vector__XXX
SG_ IVT_Result_U3_mV : 23|32@0- (1,0) [-2147483648|2147483647] "mV" Vector__XXX

BO_ 1573 IVT1_Msg_Result_T: 6 Vector__XXX
SG_ IVT1_Result_T_systemError : 15|1@0+ (1,0) [0|1] "" Vector__XXX
SG_ IVT1_Result_T_OCS : 12|1@0+ (1,0) [0|1] "" Vector__XXX
SG_ IVT1_Result_T_overallMeasError : 14|1@0+ (1,0) [0|1] "" Vector__XXX
SG_ IVT1_Result_T_channelMeasError : 13|1@0+ (1,0) [0|1] "" Vector__XXX
SG_ IVT1_ID_Result_T : 7|8@0+ (1,0) [4|4] "" Vector__XXX
SG_ IVT1_MsgCount_Result_T : 11|4@0+ (1,0) [0|15] "" Vector__XXX
SG_ IVT1_Result_T_ddegC : 23|32@0- (0.1,0) [-214748364.8|214748364.7] "ddegCC" Vector__XXX

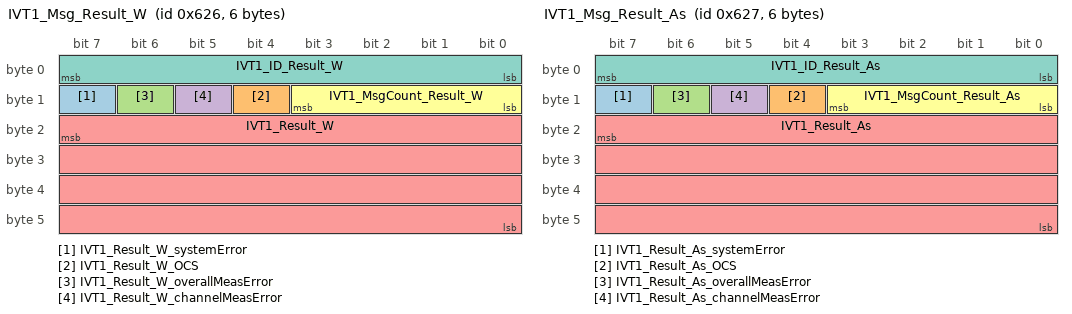
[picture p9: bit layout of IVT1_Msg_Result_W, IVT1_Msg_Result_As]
BO_ 1574 IVT1_Msg_Result_W: 6 Vector__XXX
SG_ IVT1_Result_W_systemError : 15|1@0+ (1,0) [0|1] "" Vector__XXX
SG_ IVT1_Result_W_OCS : 12|1@0+ (1,0) [0|1] "" Vector__XXX
SG_ IVT1_Result_W_overallMeasError : 14|1@0+ (1,0) [0|1] "" Vector__XXX
SG_ IVT1_Result_W_channelMeasError : 13|1@0+ (1,0) [0|1] "" Vector__XXX
SG_ IVT1_Result_W : 23|32@0- (1,0) [-2147483648|2147483647] "W" Vector__XXX
SG_ IVT1_MsgCount_Result_W : 11|4@0+ (1,0) [0|15] "" Vector__XXX
SG_ IVT1_ID_Result_W : 7|8@0+ (1,0) [5|5] "" Vector__XXX

BO_ 1575 IVT1_Msg_Result_As: 6 Vector__XXX
SG_ IVT1_Result_As_systemError : 15|1@0+ (1,0) [0|1] "" Vector__XXX
SG_ IVT1_Result_As_OCS : 12|1@0+ (1,0) [0|1] "" Vector__XXX
SG_ IVT1_Result_As_overallMeasError : 14|1@0+ (1,0) [0|1] "" Vector__XXX
SG_ IVT1_Result_As_channelMeasError : 13|1@0+ (1,0) [0|1] "" Vector__XXX
SG_ IVT1_Result_As : 23|32@0- (1,0) [-2147483648|2147483647] "As" Vector__XXX
SG_ IVT1_MsgCount_Result_As : 11|4@0+ (1,0) [0|15] "" Vector__XXX
SG_ IVT1_ID_Result_As : 7|8@0+ (1,0) [6|6] "" Vector__XXX

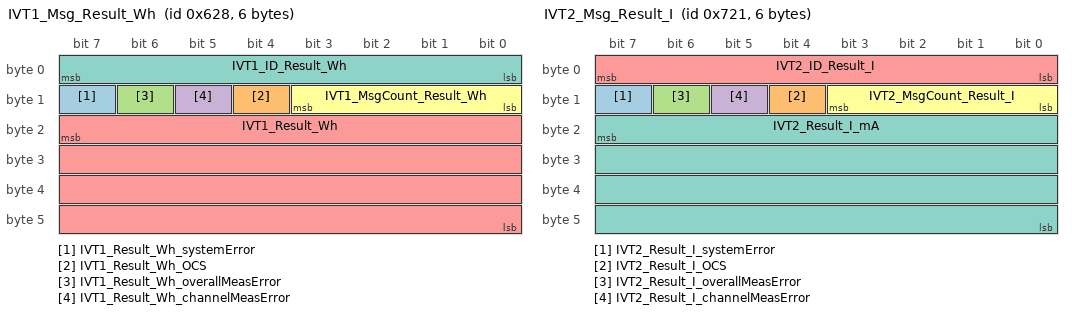
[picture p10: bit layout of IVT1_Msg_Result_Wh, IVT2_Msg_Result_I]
BO_ 1576 IVT1_Msg_Result_Wh: 6 Vector__XXX
SG_ IVT1_Result_Wh_systemError : 15|1@0+ (1,0) [0|1] "" Vector__XXX
SG_ IVT1_Result_Wh_OCS : 12|1@0+ (1,0) [0|1] "" Vector__XXX
SG_ IVT1_Result_Wh_overallMeasError : 14|1@0+ (1,0) [0|1] "" Vector__XXX
SG_ IVT1_Result_Wh_channelMeasError : 13|1@0+ (1,0) [0|1] "" Vector__XXX
SG_ IVT1_Result_Wh : 23|32@0- (1,0) [-2147483648|2147483647] "Wh" Vector__XXX
SG_ IVT1_MsgCount_Result_Wh : 11|4@0+ (1,0) [0|15] "" Vector__XXX
SG_ IVT1_ID_Result_Wh : 7|8@0+ (1,0) [7|7] "" Vector__XXX

BO_ 1825 IVT2_Msg_Result_I: 6 Vector__XXX
SG_ IVT2_Result_I_systemError : 15|1@0+ (1,0) [0|1] "" Vector__XXX
SG_ IVT2_Result_I_OCS : 12|1@0+ (1,0) [0|1] "" Vector__XXX
SG_ IVT2_Result_I_overallMeasError : 14|1@0+ (1,0) [0|1] "" Vector__XXX
SG_ IVT2_Result_I_channelMeasError : 13|1@0+ (1,0) [0|1] "" Vector__XXX
SG_ IVT2_ID_Result_I : 7|8@0+ (1,0) [0|255] "" Vector__XXX
SG_ IVT2_MsgCount_Result_I : 11|4@0+ (1,0) [0|15] "" Vector__XXX
SG_ IVT2_Result_I_mA : 23|32@0- (1,0) [-2147483648|2147483647] "mA" Vector__XXX

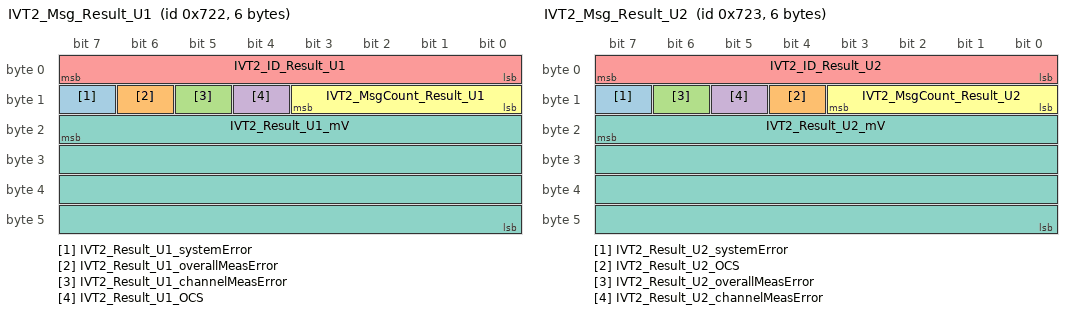
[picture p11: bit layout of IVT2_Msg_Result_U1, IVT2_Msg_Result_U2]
BO_ 1826 IVT2_Msg_Result_U1: 6 Vector__XXX
SG_ IVT2_Result_U1_systemError : 15|1@0+ (1,0) [0|1] "" Vector__XXX
SG_ IVT2_Result_U1_overallMeasError : 14|1@0+ (1,0) [0|1] "" Vector__XXX
SG_ IVT2_Result_U1_channelMeasError : 13|1@0+ (1,0) [0|1] "" Vector__XXX
SG_ IVT2_Result_U1_OCS : 12|1@0+ (1,0) [0|1] "" Vector__XXX
SG_ IVT2_ID_Result_U1 : 7|8@0+ (1,0) [1|1] "" Vector__XXX
SG_ IVT2_MsgCount_Result_U1 : 11|4@0+ (1,0) [0|15] "" Vector__XXX
SG_ IVT2_Result_U1_mV : 23|32@0- (1,0) [-2147483648|2147483647] "mV" Vector__XXX

BO_ 1827 IVT2_Msg_Result_U2: 6 Vector__XXX
SG_ IVT2_Result_U2_systemError : 15|1@0+ (1,0) [0|1] "" Vector__XXX
SG_ IVT2_Result_U2_OCS : 12|1@0+ (1,0) [0|1] "" Vector__XXX
SG_ IVT2_Result_U2_overallMeasError : 14|1@0+ (1,0) [0|1] "" Vector__XXX
SG_ IVT2_Result_U2_channelMeasError : 13|1@0+ (1,0) [0|1] "" Vector__XXX
SG_ IVT2_ID_Result_U2 : 7|8@0+ (1,0) [2|2] "" Vector__XXX
SG_ IVT2_MsgCount_Result_U2 : 11|4@0+ (1,0) [0|15] "" Vector__XXX
SG_ IVT2_Result_U2_mV : 23|32@0- (1,0) [-2147483648|2147483647] "mV" Vector__XXX

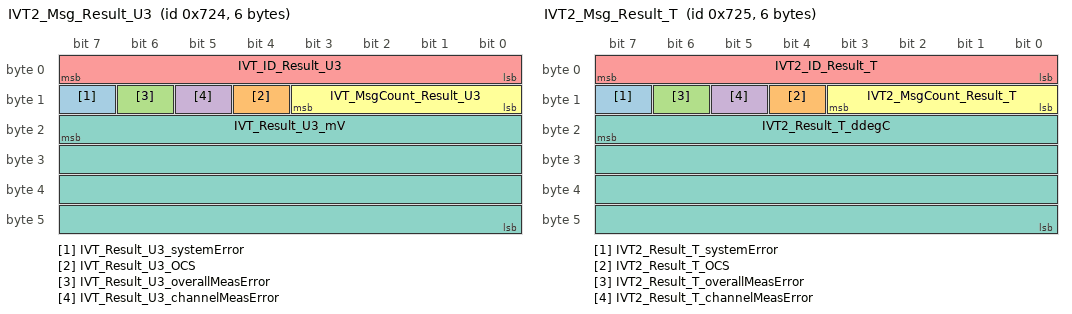
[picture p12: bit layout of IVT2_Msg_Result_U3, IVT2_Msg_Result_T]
BO_ 1828 IVT2_Msg_Result_U3: 6 Vector__XXX
SG_ IVT_Result_U3_systemError : 15|1@0+ (1,0) [0|1] "" Vector__XXX
SG_ IVT_Result_U3_OCS : 12|1@0+ (1,0) [0|1] "" Vector__XXX
SG_ IVT_Result_U3_overallMeasError : 14|1@0+ (1,0) [0|1] "" Vector__XXX
SG_ IVT_Result_U3_channelMeasError : 13|1@0+ (1,0) [0|1] "" Vector__XXX
SG_ IVT_ID_Result_U3 : 7|8@0+ (1,0) [3|3] "" Vector__XXX
SG_ IVT_MsgCount_Result_U3 : 11|4@0+ (1,0) [0|15] "" Vector__XXX
SG_ IVT_Result_U3_mV : 23|32@0- (1,0) [-2147483648|2147483647] "mV" Vector__XXX

BO_ 1829 IVT2_Msg_Result_T: 6 Vector__XXX
SG_ IVT2_Result_T_systemError : 15|1@0+ (1,0) [0|1] "" Vector__XXX
SG_ IVT2_Result_T_OCS : 12|1@0+ (1,0) [0|1] "" Vector__XXX
SG_ IVT2_Result_T_overallMeasError : 14|1@0+ (1,0) [0|1] "" Vector__XXX
SG_ IVT2_Result_T_channelMeasError : 13|1@0+ (1,0) [0|1] "" Vector__XXX
SG_ IVT2_ID_Result_T : 7|8@0+ (1,0) [4|4] "" Vector__XXX
SG_ IVT2_MsgCount_Result_T : 11|4@0+ (1,0) [0|15] "" Vector__XXX
SG_ IVT2_Result_T_ddegC : 23|32@0- (0.1,0) [-214748364.8|214748364.7] "ddegC" Vector__XXX

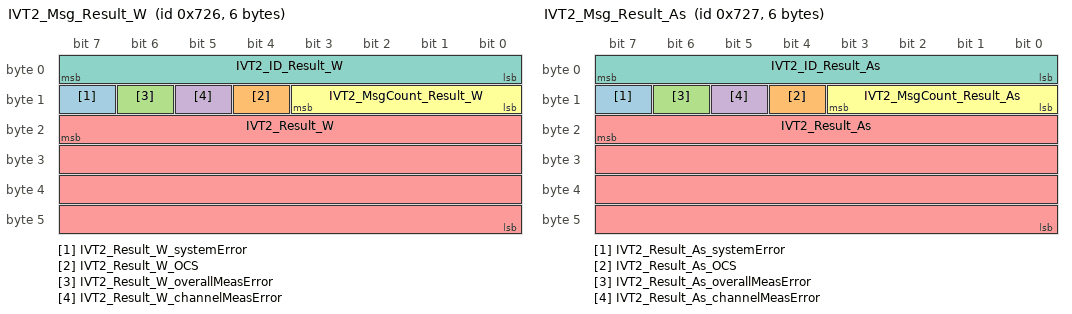
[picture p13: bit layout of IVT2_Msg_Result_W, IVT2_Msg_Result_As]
BO_ 1830 IVT2_Msg_Result_W: 6 Vector__XXX
SG_ IVT2_Result_W_systemError : 15|1@0+ (1,0) [0|1] "" Vector__XXX
SG_ IVT2_Result_W_OCS : 12|1@0+ (1,0) [0|1] "" Vector__XXX
SG_ IVT2_Result_W_overallMeasError : 14|1@0+ (1,0) [0|1] "" Vector__XXX
SG_ IVT2_Result_W_channelMeasError : 13|1@0+ (1,0) [0|1] "" Vector__XXX
SG_ IVT2_Result_W : 23|32@0- (1,0) [-2147483648|2147483647] "W" Vector__XXX
SG_ IVT2_MsgCount_Result_W : 11|4@0+ (1,0) [0|15] "" Vector__XXX
SG_ IVT2_ID_Result_W : 7|8@0+ (1,0) [5|5] "" Vector__XXX

BO_ 1831 IVT2_Msg_Result_As: 6 Vector__XXX
SG_ IVT2_Result_As_systemError : 15|1@0+ (1,0) [0|1] "" Vector__XXX
SG_ IVT2_Result_As_OCS : 12|1@0+ (1,0) [0|1] "" Vector__XXX
SG_ IVT2_Result_As_overallMeasError : 14|1@0+ (1,0) [0|1] "" Vector__XXX
SG_ IVT2_Result_As_channelMeasError : 13|1@0+ (1,0) [0|1] "" Vector__XXX
SG_ IVT2_Result_As : 23|32@0- (1,0) [-2147483648|2147483647] "As" Vector__XXX
SG_ IVT2_MsgCount_Result_As : 11|4@0+ (1,0) [0|15] "" Vector__XXX
SG_ IVT2_ID_Result_As : 7|8@0+ (1,0) [6|6] "" Vector__XXX

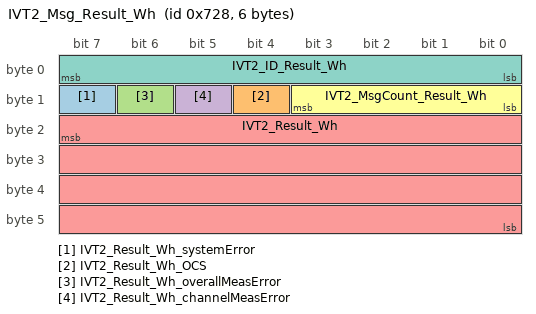
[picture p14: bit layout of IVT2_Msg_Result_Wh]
BO_ 1832 IVT2_Msg_Result_Wh: 6 Vector__XXX
SG_ IVT2_Result_Wh_systemError : 15|1@0+ (1,0) [0|1] "" Vector__XXX
SG_ IVT2_Result_Wh_OCS : 12|1@0+ (1,0) [0|1] "" Vector__XXX
SG_ IVT2_Result_Wh_overallMeasError : 14|1@0+ (1,0) [0|1] "" Vector__XXX
SG_ IVT2_Result_Wh_channelMeasError : 13|1@0+ (1,0) [0|1] "" Vector__XXX
SG_ IVT2_Result_Wh : 23|32@0- (1,0) [-2147483648|2147483647] "Wh" Vector__XXX
SG_ IVT2_MsgCount_Result_Wh : 11|4@0+ (1,0) [0|15] "" Vector__XXX
SG_ IVT2_ID_Result_Wh : 7|8@0+ (1,0) [7|7] "" Vector__XXX

CM_ SG_ 546 foxBMS_packCurrent "Battery pack current";
CM_ SG_ 546 foxBMS_batteryVoltage "Battery voltage between negative and positive pole of the battery";
CM_ SG_ 546 foxBMS_busVoltage "Battery voltage between negative pole and after main positive contactor";
CM_ SG_ 546 foxBMS_packPower "Battery power";
CM_ SG_ 548 foxBMS_maxChargeCurrent "Maximum battery pack charge current";
CM_ SG_ 548 foxBMS_maxDischargeCurrent "Maximum battery pack discharge current";
CM_ SG_ 547 foxBMS_minimumCellVoltage "Minimum cell voltage of all connected strings, if no string connected maximum value of whole system is transmitted";
CM_ SG_ 547 foxBMS_maximumCellVoltage "Maximum cell voltage of all connected strings, if no string connected maximum value of whole system is transmitted";
CM_ SG_ 547 foxBMS_maximumCellTemp "Maximum cell temperature of all connected strings, if no string connected maximum value of whole system is transmitted";
CM_ SG_ 547 foxBMS_minimumCellTemp "Minium cell temperature of all connected string, if no string connected maximum value of whole system is transmitted";
CM_ BO_ 640 "Message contains string voltage, current and power";
CM_ BO_ 643 "Message contains energy counting value";
CM_ SG_ 643 String0_energyCount "Current sensor string 0 energy counting value";
CM_ SG_ 643 String1_energyCount1 "Current sensor string 1 energy counting value";
CM_ SG_ 643 String1_energyCount2 "Current sensor string 2 energy counting value";
CM_ SG_ 549 foxBMS_packSoc "SOC currently connected to HV bus (100% if all strings connected and all strings at 100%)";
CM_ SG_ 549 foxBMS_packSoe "SOE currently connected to HV bus (100% if all strings connected and all strings at 100%)";
CM_ SG_ 549 foxBMS_packEnergy "Energy left in Wh that is currently connected to HV bus";
CM_ SG_ 560 foxBMS_ModeRequest "0x0: Disconnect strings from HV bus, 0x01: Connect strings to HV bus to start discharge, 0x02: Connect strings to HV bus to start charging";
CM_ SG_ 560 foxBMS_activateBalancing "0: Deactivate balancing, 1: Activate balancing";
CM_ SG_ 560 foxBMS_balancingThreshold "Required voltage difference to minimum cell voltage to activate balancing";
CM_ SG_ 560 foxBMS_externallyPrecharged "0x0: HV bus not externally precharged, 0x01: HV bus externally precharged";
CM_ SG_ 560 foxBMS_resetFlags "0x01: reset persistent flags";
CM_ SG_ 560 foxBMS_chargerConnected "0x00: charger not connected, 0x01: charger connected";
CM_ SG_ 560 foxBMS_disableInsulationMon "0x00: Check battery system insulation, 0x01: Do not check insulation of battery system";
CM_ SG_ 560 foxBMS_heaterOverride_ON "0: no override active, 1: override active -> force heater on";
CM_ SG_ 560 foxBMS_heaterOverride_OFF "0: no override active, 1: override active -> force heater off";
CM_ BO_ 544 "Message contains foxBMS state";
CM_ SG_ 544 foxBMS_generalError "0x00: No error detected, 0x01: Error detected";
CM_ SG_ 544 foxBMS_generalWarning "0x00: No warning detected, 0x01: Warning detected";
CM_ SG_ 544 foxBMS_Error_dieTemperatureMCU "0x00: No error, 0x01: Error detected";
CM_ SG_ 544 foxBMS_Error_OvertempPCB "foxBMS Master-PCB: 0x00: No error, 0x01: Error detected";
CM_ SG_ 544 foxBMS_Error_UndertempPCB "foxBMS Master-PCB: 0x00: No error, 0x01: Error detected";
CM_ SG_ 544 foxBMS_Error_PrechargeVolt "0x00: precharging successful, 0x01: precharge aborted because of voltage difference";
CM_ SG_ 544 foxBMS_Error_PrechargeCurrent "0x00: precharging successful, 0x01: precharge aborted because current limit violated";
CM_ SG_ 544 foxBMS_heaterState "0x00: Heater not activated, 0x01: Heater activated";
CM_ SG_ 544 foxBMS_coolingState "0x00: Cooling not activated, 0x01: Cooling activated";
CM_ SG_ 544 foxBMS_insulationMonitoring "0x00: insulation monitoring active, 0x01: insulation monitoring not active";
CM_ SG_ 544 foxBMS_chargingComplete "0x01: charging complete";
CM_ SG_ 544 foxBMS_EmergencyShutoff "The BMS is preparing to open the contactors soon due to detected error";
CM_ SG_ 544 foxBMS_MainFuseBlown "0x00: fuse okay, 0x01: fuse blown";
CM_ SG_ 544 foxBMS_Error_Interlock "0x00: interlock okay, 0x01: interlock open";
CM_ BO_ 545 "Message contains string related error and warning flags";
CM_ SG_ 545 String0_stringConnected "0x00: String not connected, 0x01: String connected to HV bus";
CM_ SG_ 545 String0_balancing_active "0x00: No balancing active, 0x01: Balancing in this string active";
CM_ SG_ 545 String0_Err_overtemp_charge "0x00: No error, 0x01: Error: Flag will be set if maximum cell temperature is above 45 degree celsius.";
CM_ SG_ 545 String0_Err_undertemp_charge "0x00: No error, 0x01: Error: Flag will be set if minimum cell temperature is below 0 degree celsius.";
CM_ SG_ 545 String0_Err_overtemp_discharge "0x00: No error, 0x01: Error: Flag will be set if maximum cell temperature is above 60 degree celsius.";
CM_ SG_ 545 String0_Err_undertemp_discharge "0x00: No error, 0x01: Error: Flag will be set if minimum cell temperature is below -20 degree celsius.";
CM_ SG_ 545 String0_Err_Overcurrent_charge "0x00: No error, 0x01: Error: Flag will be set if string charge current is above 30400mA.";
CM_ SG_ 545 String0_Err_Overcurre_discharge "0x00: No error, 0x01: Error: Flag will be set if discharge current is above maximum string current.";
CM_ SG_ 545 String0_Err_Overvoltage "0x00: No error, 0x01: Error: Flag will be set if maximum cell voltage is above 4200mV.";
CM_ SG_ 545 String0_Err_Undervoltage "0x00: No error, 0x01: Error: Flag will be set if minimum cell voltage is below 3000mV. This equals roughly 4% remaining SOC. Minimum datasheet values if 2500mV.";
CM_ SG_ 545 String0_Err_deep_discharge "0x00: No error, 0x01: Error";
CM_ SG_ 545 String0_Err_CS_currentMeas "0x00: No error, 0x01: Error";
CM_ SG_ 545 String0_Err_positiveContactor "0x00: No error, 0x01: Error";
CM_ SG_ 545 String0_Err_openWire "0x00: No error, 0x01: Error";
CM_ SG_ 545 String0_openWireNumber "Number of first open wire that has been detected in this string";
CM_ SG_ 545 String0_Err_plaus_cell_volt "0x00: No error, 0x01: Error";
CM_ SG_ 545 String0_Err_plaus_cell_temp "0x00: No error, 0x01: Error";
CM_ SG_ 545 String0_Err_plaus_string_volt "0x00: No error, 0x01: Error";
CM_ SG_ 545 String0_Err_slave_hardware "0x00: No error, 0x01: Error";
CM_ SG_ 545 String0_Err_dsyChainPrim_Comm "0x00: No error, 0x01: Error (i.e. SPI)";
CM_ SG_ 545 String0_Err_dsyChainPrim_CRC "0x00: No error, 0x01: Error";
CM_ SG_ 545 String0_Err_dsyChainRedun_Comm "0x00: No error, 0x01: Error";
CM_ SG_ 545 String0_Err_dsyChainRedun_CRC "0x00: No error, 0x01: Error";
CM_ SG_ 545 String0_Err_dsyPrim_voltMeasOor "0x00: No error, 0x01: Error";
CM_ SG_ 545 String0_Err_dsyRedun_voltMeasOor "0x00: No error, 0x01: Error";
CM_ SG_ 545 String0_Err_dsyPrim_tempMeasOor "0x00: No error, 0x01: Error";
CM_ SG_ 545 String0_Err_dsyRedun_tempMeasOor "0x00: No error, 0x01: Error";
CM_ SG_ 545 String0_Err_CS_coulombCountMeas "0x00: No error, 0x01: Error";
CM_ SG_ 545 String0_Err_CS_energyCountMeas "0x00: No error, 0x01: Error";
CM_ SG_ 545 String0_Err_plaus_volt_spread "0x00: No error, 0x01: Error";
CM_ SG_ 545 String0_Err_plaus_temp_spread "0x00: No error, 0x01: Error";
CM_ SG_ 545 String1_stringConnected "0x00: String not connected, 0x01: String connected to HV bus";
CM_ SG_ 545 String1_balancing_active "0x00: No balancing active, 0x01: Balancing in this string active";
CM_ SG_ 545 String1_Err_overtemp_charge "0x00: No error, 0x01: Error: Flag will be set if maximum cell temperature is above 45 degree celsius.";
CM_ SG_ 545 String1_Err_undertemp_charge "0x00: No error, 0x01: Error: Flag will be set if minimum cell temperature is below 0 degree celsius.";
CM_ SG_ 545 String1_Err_overtemp_discharge "0x00: No error, 0x01: Error: Flag will be set if maximum cell temperature is above 60 degree celsius.";
CM_ SG_ 545 String1_Err_undertemp_discharge "0x00: No error, 0x01: Error: Flag will be set if minimum cell temperature is below -20 degree celsius.";
CM_ SG_ 545 String1_Err_Overcurrent_charge "0x00: No error, 0x01: Error: Flag will be set if string charge current is above 30400mA.";
CM_ SG_ 545 String1_Err_Overcurre_discharge "0x00: No error, 0x01: Error: Flag will be set if discharge current is above maximum string current.";
CM_ SG_ 545 String1_Err_Overvoltage "0x00: No error, 0x01: Error: Flag will be set if maximum cell voltage is above 4200mV.";
CM_ SG_ 545 String1_Err_Undervoltage "0x00: No error, 0x01: Error: Flag will be set if minimum cell voltage is below 3000mV. This equals roughly 4% remaining SOC. Minimum datasheet values if 2500mV.";
CM_ SG_ 545 String1_Err_deep_discharge "0x00: No error, 0x01: Error";
CM_ SG_ 545 String1_Err_CS_currentMeas "0x00: No error, 0x01: Error";
CM_ SG_ 545 String1_Err_positiveContactor "0x00: No error, 0x01: Error";
CM_ SG_ 545 String1_Err_openWire "0x00: No error, 0x01: Error";
CM_ SG_ 545 String1_openWireNumber "Number of first open wire that has been detected in this string";
CM_ SG_ 545 String1_Err_plaus_cell_volt "0x00: No error, 0x01: Error";
CM_ SG_ 545 String1_Err_plaus_cell_temp "0x00: No error, 0x01: Error";
CM_ SG_ 545 String1_Err_plaus_string_volt "0x00: No error, 0x01: Error";
CM_ SG_ 545 String1_Err_slave_hardware "0x00: No error, 0x01: Error";
CM_ SG_ 545 String1_Err_dsyChainPrim_Comm "0x00: No error, 0x01: Error (i.e. SPI)";
CM_ SG_ 545 String1_Err_dsyChainPrim_CRC "0x00: No error, 0x01: Error";
CM_ SG_ 545 String1_Err_dsyChainRedun_Comm "0x00: No error, 0x01: Error";
CM_ SG_ 545 String1_Err_dsyChainRedun_CRC "0x00: No error, 0x01: Error";
CM_ SG_ 545 String1_Err_dsyPrim_voltMeasOor "0x00: No error, 0x01: Error";
CM_ SG_ 545 String1_Err_dsyRedun_voltMeasOor "0x00: No error, 0x01: Error";
CM_ SG_ 545 String1_Err_dsyPrim_tempMeasOor "0x00: No error, 0x01: Error";
CM_ SG_ 545 String1_Err_dsyRedun_tempMeasOor "0x00: No error, 0x01: Error";
CM_ SG_ 545 String1_Err_CS_coulombCountMeas "0x00: No error, 0x01: Error";
CM_ SG_ 545 String1_Err_CS_energyCountMeas "0x00: No error, 0x01: Error";
CM_ SG_ 545 String1_Err_plaus_volt_spread "0x00: No error, 0x01: Error";
CM_ SG_ 545 String1_Err_plaus_temp_spread "0x00: No error, 0x01: Error";
CM_ SG_ 545 String2_stringConnected "0x00: String not connected, 0x01: String connected to HV bus";
CM_ SG_ 545 String2_balancing_active "0x00: No balancing active, 0x01: Balancing in this string active";
CM_ SG_ 545 String2_Err_overtemp_charge "0x00: No error, 0x01: Error: Flag will be set if maximum cell temperature is above 45 degree celsius.";
CM_ SG_ 545 String2_Err_undertemp_charge "0x00: No error, 0x01: Error: Flag will be set if minimum cell temperature is below 0 degree celsius.";
CM_ SG_ 545 String2_Err_overtemp_discharge "0x00: No error, 0x01: Error: Flag will be set if maximum cell temperature is above 60 degree celsius.";
CM_ SG_ 545 String2_Err_undertemp_discharge "0x00: No error, 0x01: Error: Flag will be set if minimum cell temperature is below -20 degree celsius.";
CM_ SG_ 545 String2_Err_Overcurrent_charge "0x00: No error, 0x01: Error: Flag will be set if string charge current is above 30400mA.";
CM_ SG_ 545 String2_Err_Overcurre_discharge "0x00: No error, 0x01: Error: Flag will be set if discharge current is above maximum string current.";
CM_ SG_ 545 String2_Err_Overvoltage "0x00: No error, 0x01: Error: Flag will be set if maximum cell voltage is above 4200mV.";
CM_ SG_ 545 String2_Err_Undervoltage "0x00: No error, 0x01: Error: Flag will be set if minimum cell voltage is below 3000mV. This equals roughly 4% remaining SOC. Minimum datasheet values if 2500mV.";
CM_ SG_ 545 String2_Err_deep_discharge "0x00: No error, 0x01: Error";
CM_ SG_ 545 String2_Err_CS_currentMeas "0x00: No error, 0x01: Error";
CM_ SG_ 545 String2_Err_positiveContactor "0x00: No error, 0x01: Error";
CM_ SG_ 545 String2_Err_openWire "0x00: No error, 0x01: Error";
CM_ SG_ 545 String2_openWireNumber "Number of first open wire that has been detected in this string";
CM_ SG_ 545 String2_Err_plaus_cell_volt "0x00: No error, 0x01: Error";
CM_ SG_ 545 String2_Err_plaus_cell_temp "0x00: No error, 0x01: Error";
CM_ SG_ 545 String2_Err_plaus_string_volt "0x00: No error, 0x01: Error";
CM_ SG_ 545 String2_Err_slave_hardware "0x00: No error, 0x01: Error";
CM_ SG_ 545 String2_Err_dsyChainPrim_Comm "0x00: No error, 0x01: Error (i.e. SPI)";
CM_ SG_ 545 String2_Err_dsyChainPrim_CRC "0x00: No error, 0x01: Error";
CM_ SG_ 545 String2_Err_dsyChainRedun_Comm "0x00: No error, 0x01: Error";
CM_ SG_ 545 String2_Err_dsyChainRedun_CRC "0x00: No error, 0x01: Error";
CM_ SG_ 545 String2_Err_dsyPrim_voltMeasOor "0x00: No error, 0x01: Error";
CM_ SG_ 545 String2_Err_dsyRedun_voltMeasOor "0x00: No error, 0x01: Error";
CM_ SG_ 545 String2_Err_dsyPrim_tempMeasOor "0x00: No error, 0x01: Error";
CM_ SG_ 545 String2_Err_dsyRedun_tempMeasOor "0x00: No error, 0x01: Error";
CM_ SG_ 545 String2_Err_CS_coulombCountMeas "0x00: No error, 0x01: Error";
CM_ SG_ 545 String2_Err_CS_energyCountMeas "0x00: No error, 0x01: Error";
CM_ SG_ 545 String2_Err_plaus_volt_spread "0x00: No error, 0x01: Error";
CM_ SG_ 545 String2_Err_plaus_temp_spread "0x00: No error, 0x01: Error";
CM_ BO_ 641 "Message contains minimum and maximum cell temperature and cell voltage values of respective string";
CM_ SG_ 641 String0_minimumCellVoltage "Minimum cell voltage in this string";
CM_ SG_ 641 String0_maximumCellVoltage "Maximum cell voltage in this string";
CM_ SG_ 641 String0_maximumCellTemperature "Maximum cell temperature in this string";
CM_ SG_ 641 String0_minimumCellTemperature "Minium cell temperature in this string";
CM_ SG_ 641 String1_minimumCellVoltage "Minimum cell voltage in this string";
CM_ SG_ 641 String1_maximumCellVoltage "Maximum cell voltage in this string";
CM_ SG_ 641 String1_maximumCellTemperature "Maximum cell temperature in this string";
CM_ SG_ 641 String1_minimumCellTemperature "Minium cell temperature in this string";
CM_ SG_ 641 String2_minimumCellVoltage "Minimum cell voltage in this string";
CM_ SG_ 641 String2_maximumCellVoltage "Maximum cell voltage in this string";
CM_ SG_ 641 String2_maximumCellTemperature "Maximum cell temperature in this string";
CM_ SG_ 641 String2_minimumCellTemperature "Minium cell temperature in this string";
CM_ BO_ 642 "Message contains SOC, SOE and SOH state estimations";
CM_ SG_ 642 String0_SOE "SOE is depending on current direction, if battery system is charging: SOE_max is transmitted, else SOE_min";
CM_ SG_ 642 String0_Energy_Wh "Remaining energy left in this string";
CM_ SG_ 642 String1_SOE "SOE is depending on current direction, if battery system is charging: SOE_max is transmitted, else SOE_min";
CM_ SG_ 642 String1_Energy_Wh "Remaining energy left in this string";
CM_ SG_ 642 String2_SOE "SOE is depending on current direction, if battery system is charging: SOE_max is transmitted, else SOE_min";
CM_ SG_ 642 String2_Energy_Wh "Remaining energy left in this string";
CM_ BO_ 512 "Reserved - for debug/development purpose only";
CM_ BO_ 1313 "Current sensor string 0: current";
CM_ BO_ 1314 "Current sensor string 0: voltage 1";
CM_ BO_ 1315 "Current sensor string 0: voltage 2";
CM_ BO_ 1316 "Current sensor string 0: voltage 3";
CM_ BO_ 1317 "Current sensor string 0: temperature";
CM_ BO_ 1318 "Current sensor string 0: power";
CM_ BO_ 1319 "Current sensor string 0: coulomb counting";
CM_ BO_ 1320 "Current sensor string 0: energy counting";
CM_ BO_ 1569 "Current sensor string 1: current";
CM_ BO_ 1570 "Current sensor string 1: voltage 1";
CM_ BO_ 1571 "Current sensor string 1: voltage 2";
CM_ BO_ 1572 "Current sensor string 1: voltage 3";
CM_ BO_ 1573 "Current sensor string 1: temperature";
CM_ BO_ 1574 "Current sensor string 1: power";
CM_ BO_ 1575 "Current sensor string 1: coulomb counting";
CM_ BO_ 1576 "Current sensor string 1: energy counting";
CM_ BO_ 1825 "Current sensor string 2: current";
CM_ BO_ 1826 "Current sensor string 2: voltage 1";
CM_ BO_ 1827 "Current sensor string 2: voltage 2";
CM_ BO_ 1828 "Current sensor string 2: voltage 3";
CM_ BO_ 1829 "Current sensor string 2: temperature";
CM_ BO_ 1830 "Current sensor string 2: power";
CM_ BO_ 1831 "Current sensor string 2: coulomb counting";
CM_ BO_ 1832 "Current sensor string 2: energy counting";

BA_DEF_  "BusType" STRING ;
BA_DEF_ SG_  "GenSigStartValue" FLOAT -3.4E+038 3.4E+038;

BA_DEF_DEF_  "BusType" "CAN";
BA_DEF_DEF_  "GenSigStartValue" 0;

BA_ "GenSigStartValue" SG_ 1314 IVT0_ID_Result_U1 1;
BA_ "GenSigStartValue" SG_ 1315 IVT0_ID_Result_U2 2;
BA_ "GenSigStartValue" SG_ 1316 IVT_ID_Result_U3 3;
BA_ "GenSigStartValue" SG_ 1317 IVT0_ID_Result_T 4;
BA_ "GenSigStartValue" SG_ 1318 IVT0_ID_Result_W 5;
BA_ "GenSigStartValue" SG_ 1319 IVT0_ID_Result_As 6;
BA_ "GenSigStartValue" SG_ 1320 IVT0_ID_Result_Wh 7;
BA_ "GenSigStartValue" SG_ 1570 IVT1_ID_Result_U1 1;
BA_ "GenSigStartValue" SG_ 1571 IVT1_ID_Result_U2 2;
BA_ "GenSigStartValue" SG_ 1572 IVT_ID_Result_U3 3;
BA_ "GenSigStartValue" SG_ 1573 IVT1_ID_Result_T 4;
BA_ "GenSigStartValue" SG_ 1574 IVT1_ID_Result_W 5;
BA_ "GenSigStartValue" SG_ 1575 IVT1_ID_Result_As 6;
BA_ "GenSigStartValue" SG_ 1576 IVT1_ID_Result_Wh 7;
BA_ "GenSigStartValue" SG_ 1826 IVT2_ID_Result_U1 1;
BA_ "GenSigStartValue" SG_ 1827 IVT2_ID_Result_U2 2;
BA_ "GenSigStartValue" SG_ 1828 IVT_ID_Result_U3 3;
BA_ "GenSigStartValue" SG_ 1829 IVT2_ID_Result_T 4;
BA_ "GenSigStartValue" SG_ 1830 IVT2_ID_Result_W 5;
BA_ "GenSigStartValue" SG_ 1831 IVT2_ID_Result_As 6;
BA_ "GenSigStartValue" SG_ 1832 IVT2_ID_Result_Wh 7;

VAL_ 640 foxBMS_StringValues_Mux 0 "mux_valuesString_0" 1 "mux_valuesString_1" 2 "mux_valuesString_2" ;
VAL_ 643 foxBMS_StringValues2_Mux 0 "mux_values2String_0" 1 "mux_values2String_1" 2 "mux_values2String_2" ;
VAL_ 576 foxBMS_CellVoltage_Mux 0 "mux_cellVoltage_0_3" 1 "mux_cellVoltage_4_7" 2 "mux_cellVoltage_8_11" 3 "mux_cellVoltage_12_15" 4 "mux_cellVoltage_16_19" 5 "mux_cellVoltage_20_23" 6 "mux_cellVoltage_24_27" 7 "mux_cellVoltage_28_31" 8 "mux_cellVoltage_32_35" 9 "mux_cellVoltage_36_39" 10 "mux_cellVoltage_40_43" 11 "mux_cellVoltage_44_47" 12 "mux_cellVoltage_48_51" 13 "mux_cellVoltage_52_55" 14 "mux_cellVoltage_56_59" 15 "mux_cellVoltage_60_63" 16 "mux_cellVoltage_64_67" 17 "mux_cellVoltage_68_71" 18 "mux_cellVoltage_72_75" 19 "mux_cellVoltage_76_79" 20 "mux_cellVoltage_80_83" 21 "mux_cellVoltage_84_87" 22 "mux_cellVoltage_88_91" 23 "mux_cellVoltage_92_95" 24 "mux_cellVoltage_96_99" 25 "mux_cellVoltage_100_103" 26 "mux_cellVoltage_104_107" 27 "mux_cellVoltage_108_111" 28 "mux_cellVoltage_112_115" 29 "mux_cellVoltage_116_119" 30 "mux_cellVoltage_120_123" 31 "mux_cellVoltage_124_127" 32 "mux_cellVoltage_128_131" 33 "mux_cellVoltage_132_135" 34 "mux_cellVoltage_136_139" 35 "mux_cellVoltage_140_143" 36 "mux_cellVoltage_144_147" 37 "mux_cellVoltage_148_151"
38 "mux_cellVoltage_152_155" 39 "mux_cellVoltage_156_159" 40 "mux_cellVoltage_160_163" 41 "mux_cellVoltage_164_167" 42 "mux_cellVoltage_168_171" 43 "mux_cellVoltage_172_175" 44 "mux_cellVoltage_176_179" 45 "mux_cellVoltage_180_183" 46 "mux_cellVoltage_184_187" 47 "mux_cellVoltage_188_191" 48 "mux_cellVoltage_192_195" 49 "mux_cellVoltage_196_199" 50 "mux_cellVoltage_200_203" 51 "mux_cellVoltage_204_207" 52 "mux_cellVoltage_208_211" 53 "mux_cellVoltage_212_215" ;
VAL_ 592 foxBMS_CellTemperature_Mux 0 "mux_cellTemperature_0_5" 1 "mux_cellTemperature_6_11" 2 "mux_cellTemperature_12_17" 3 "mux_cellTemperature_18_23" 4 "mux_cellTemperature_24_29" 5 "mux_cellTemperature_30_35" 6 "mux_cellTemperature_36_41" 7 "mux_cellTemperature_42_47" 8 "mux_cellTemperature_48_53" 9 "mux_cellTemperature_54_59" 10 "mux_cellTemperature_60_65" 11 "mux_cellTemperature_66_71" 12 "mux_cellTemperature_72_77" 13 "mux_cellTemperature_78_83" 14 "mux_cellTemperature_84_89" 15 "mux_cellTemperature_90_95" 16 "mux_cellTemperature_96_101" 17 "mux_cellTemperature_102_107" 18 "mux_cellTemperature_108_113" 19 "mux_cellTemperature_114_119" 20 "mux_cellTemperature_120_125" 21 "mux_cellTemperature_126_131" 22 "mux_cellTemperature_132_137" 23 "mux_cellTemperature_138_143" 24 "mux_cellTemperature_144_149" 25 "mux_cellTemperature_150_155" 26 "mux_cellTemperature_156_161" 27 "mux_cellTemperature_162_167" 28 "mux_cellTemperature_168_173" 29 "mux_cellTemperature_174_179" ;
VAL_ 545 foxBMS_StringState_Mux 0 "mux_stateString0" 1 "mux_stateString1" 2 "mux_stateString2" ;
VAL_ 641 foxBMS_StringMinimumMaximumValues_Mux 0 "mux_minMaxValuesString0" 1 "mux_minMaxValuesString1" 2 "mux_minMaxValuesString2" ;
VAL_ 642 foxBMS_StringStateEstimation_Mux 0 "mux_String0_SOC_SOE" 1 "mux_String1_SOC_SOE" 2 "mux_String2_SOC_SOE" ;
